VERSION ""

NS_ :

BS_:

BU_: Vector__XXX

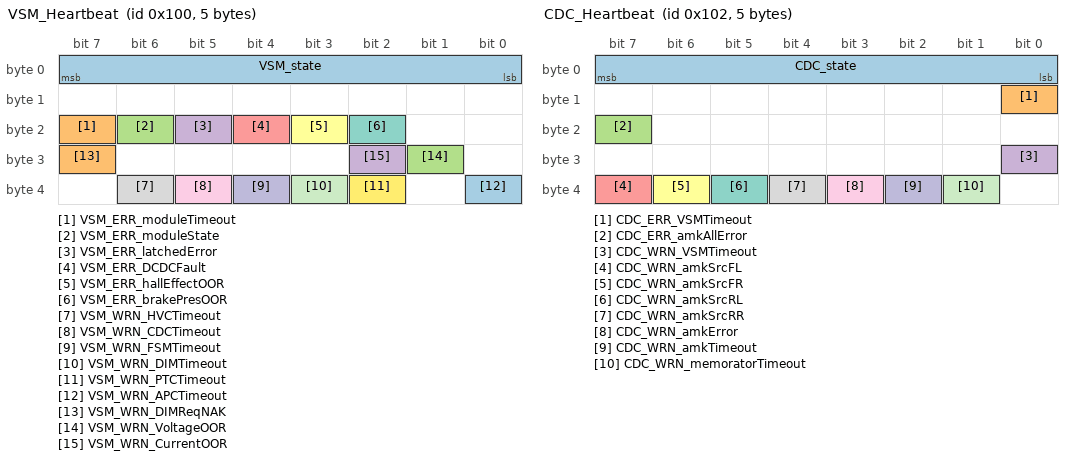
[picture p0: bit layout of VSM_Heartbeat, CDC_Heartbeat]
BO_ 256 VSM_Heartbeat: 5 Vector__XXX
SG_ VSM_state : 0|8@1+ (1,0) [0|255] "" Vector__XXX
SG_ VSM_ERR_moduleTimeout : 23|1@1+ (1,0) [0|1] "" Vector__XXX
SG_ VSM_ERR_moduleState : 22|1@1+ (1,0) [0|1] "" Vector__XXX
SG_ VSM_ERR_latchedError : 21|1@1+ (1,0) [0|1] "" Vector__XXX
SG_ VSM_ERR_DCDCFault : 20|1@1+ (1,0) [0|1] "" Vector__XXX
SG_ VSM_ERR_hallEffectOOR : 19|1@1+ (1,0) [0|1] "" Vector__XXX
SG_ VSM_ERR_brakePresOOR : 18|1@1+ (1,0) [0|1] "" Vector__XXX
SG_ VSM_WRN_HVCTimeout : 38|1@1+ (1,0) [0|1] "" Vector__XXX
SG_ VSM_WRN_CDCTimeout : 37|1@1+ (1,0) [0|1] "" Vector__XXX
SG_ VSM_WRN_FSMTimeout : 36|1@1+ (1,0) [0|1] "" Vector__XXX
SG_ VSM_WRN_DIMTimeout : 35|1@1+ (1,0) [0|1] "" Vector__XXX
SG_ VSM_WRN_PTCTimeout : 34|1@1+ (1,0) [0|1] "" Vector__XXX
SG_ VSM_WRN_APCTimeout : 32|1@1+ (1,0) [0|1] "" Vector__XXX
SG_ VSM_WRN_DIMReqNAK : 31|1@1+ (1,0) [0|1] "" Vector__XXX
SG_ VSM_WRN_VoltageOOR : 25|1@1+ (1,0) [0|1] "" Vector__XXX
SG_ VSM_WRN_CurrentOOR : 26|1@1+ (1,0) [0|1] "" Vector__XXX

BO_ 272 VSM_Status: 4 Vector__XXX
SG_ VSM_internalState : 0|8@1+ (1,0) [0|255] "" Vector__XXX
SG_ VSM_ERR_HVCTimeout : 14|1@1+ (1,0) [0|1] "" Vector__XXX
SG_ VSM_ERR_CDCTimeout : 13|1@1+ (1,0) [0|1] "" Vector__XXX
SG_ VSM_ERR_FSMTimeout : 12|1@1+ (1,0) [0|1] "" Vector__XXX
SG_ VSM_ERR_DIMTimeout : 11|1@1+ (1,0) [0|1] "" Vector__XXX
SG_ VSM_ERR_PTCTimeout : 10|1@1+ (1,0) [0|1] "" Vector__XXX
SG_ VSM_ERR_APCTimeout : 8|1@1+ (1,0) [0|1] "" Vector__XXX
SG_ VSM_ERR_HVCState : 22|1@1+ (1,0) [0|1] "" Vector__XXX
SG_ VSM_ERR_CDCState : 21|1@1+ (1,0) [0|1] "" Vector__XXX
SG_ VSM_ERR_FSMState : 20|1@1+ (1,0) [0|1] "" Vector__XXX
SG_ VSM_ERR_DIMState : 19|1@1+ (1,0) [0|1] "" Vector__XXX
SG_ VSM_ERR_PTCState : 18|1@1+ (1,0) [0|1] "" Vector__XXX
SG_ VSM_ERR_APCState : 16|1@1+ (1,0) [0|1] "" Vector__XXX
SG_ VSM_ERR_latchSoftware : 26|1@1+ (1,0) [0|1] "" Vector__XXX
SG_ VSM_ERR_latchAMS : 26|1@1+ (1,0) [0|1] "" Vector__XXX
SG_ VSM_ERR_latchIMD : 25|1@1+ (1,0) [0|1] "" Vector__XXX
SG_ VSM_ERR_latchBSPD : 24|1@1+ (1,0) [0|1] "" Vector__XXX

BO_ 512 VSM_Sensors: 8 Vector__XXX
SG_ VSM_brakePressureRear : 0|16@1+ (1,0) [0|65535] "PSI" Vector__XXX
SG_ VSM_hallEffect : 16|16@1- (0.01,0) [-327.68|327.67] "A" Vector__XXX
SG_ VSM_HE_CoulombCount : 32|32@1- (1,0) [-3.4E038|3.4E038] "C" Vector__XXX

BO_ 1296 VSM_LatchedStatus: 3 Vector__XXX
SG_ VSM_latched_ERR_HVCTimeout : 7|1@1+ (1,0) [0|1] "" Vector__XXX
SG_ VSM_latched_ERR_CDCTimeout : 6|1@1+ (1,0) [0|1] "" Vector__XXX
SG_ VSM_latched_ERR_FSMTimeout : 5|1@1+ (1,0) [0|1] "" Vector__XXX
SG_ VSM_latched_ERR_PTCTimeout : 4|1@1+ (1,0) [0|1] "" Vector__XXX
SG_ VSM_latched_ERR_DIMTimeout : 3|1@1+ (1,0) [0|1] "" Vector__XXX
SG_ VSM_latched_ERR_PTCfTimeout : 2|1@1+ (1,0) [0|1] "" Vector__XXX
SG_ VSM_latched_ERR_APCTimeout : 0|1@1+ (1,0) [0|1] "" Vector__XXX
SG_ VSM_latched_ERR_HVCState : 15|1@1+ (1,0) [0|1] "" Vector__XXX
SG_ VSM_latched_ERR_CDCState : 14|1@1+ (1,0) [0|1] "" Vector__XXX
SG_ VSM_latched_ERR_FSMState : 13|1@1+ (1,0) [0|1] "" Vector__XXX
SG_ VSM_latched_ERR_PTCState : 12|1@1+ (1,0) [0|1] "" Vector__XXX
SG_ VSM_latched_ERR_DIMState : 11|1@1+ (1,0) [0|1] "" Vector__XXX
SG_ VSM_latched_ERR_PTCfState : 10|1@1+ (1,0) [0|1] "" Vector__XXX
SG_ VSM_latched_ERR_APCState : 8|1@1+ (1,0) [0|1] "" Vector__XXX
SG_ VSM_latched_ERR_latchSoftware : 18|1@1+ (1,0) [0|1] "" Vector__XXX
SG_ VSM_latched_ERR_latchAMS : 18|1@1+ (1,0) [0|1] "" Vector__XXX
SG_ VSM_latched_ERR_latchIMD : 17|1@1+ (1,0) [0|1] "" Vector__XXX
SG_ VSM_latched_ERR_latchBSPD : 16|1@1+ (1,0) [0|1] "" Vector__XXX

BO_ 1328 VSM_PowerDiagnostic: 4 Vector__XXX
SG_ VSM_busVoltage : 0|16@1+ (1,0) [0|65535] "mV" Vector__XXX
SG_ VSM_busCurrent : 16|16@1+ (1,0) [0|65535] "mA" Vector__XXX

BO_ 257 HVC_Heartbeat: 6 Vector__XXX
SG_ HVC_Mode : 16|8@1+ (1,0) [0|255] "" Vector__XXX
SG_ HVC_State : 24|8@1+ (1,0) [0|255] "" Vector__XXX
SG_ HVC_Uptime : 40|8@1+ (1,0) [0|255] "s" Vector__XXX
SG_ HVC_ERR_PACK_UNDERVOLT : 0|1@1+ (1,0) [0|1] "" Vector__XXX
SG_ HVC_ERR_PACK_OVERVOLT : 1|1@1+ (1,0) [0|1] "" Vector__XXX
SG_ HVC_ERR_PACK_OVERCURRENT : 3|1@1+ (1,0) [0|1] "" Vector__XXX
SG_ HVC_ERR_CELL_UNDERVOLT : 4|1@1+ (1,0) [0|1] "" Vector__XXX
SG_ HVC_ERR_CELL_OVERVOLT : 5|1@1+ (1,0) [0|1] "" Vector__XXX
SG_ HVC_ERR_CELL_OVERTEMP : 6|1@1+ (1,0) [0|1] "" Vector__XXX
SG_ HVC_ERR_BMB_FAULT : 7|1@1+ (1,0) [0|1] "" Vector__XXX
SG_ HVC_ERR_BMB_TIMEOUT : 8|1@1+ (1,0) [0|1] "" Vector__XXX
SG_ HVC_ERR_CAN_TIMEOUT : 9|1@1+ (1,0) [0|1] "" Vector__XXX
SG_ HVC_ERR_RELAY : 12|1@1+ (1,0) [0|1] "" Vector__XXX
SG_ HVC_ERR_LV_UNDERVOLT : 13|1@1+ (1,0) [0|1] "" Vector__XXX
SG_ HVC_dischargeClosed : 32|1@1+ (1,0) [0|1] "" Vector__XXX
SG_ HVC_prechargeClosed : 33|1@1+ (1,0) [0|1] "" Vector__XXX
SG_ HVC_negAIRClosed : 34|1@1+ (1,0) [0|1] "" Vector__XXX
SG_ HVC_posAIRClosed : 35|1@1+ (1,0) [0|1] "" Vector__XXX
SG_ HVC_dischargeError : 36|1@1+ (1,0) [0|1] "" Vector__XXX
SG_ HVC_prechargeError : 37|1@1+ (1,0) [0|1] "" Vector__XXX
SG_ HVC_negAIRError : 38|1@1+ (1,0) [0|1] "" Vector__XXX
SG_ HVC_posAIRError : 39|1@1+ (1,0) [0|1] "" Vector__XXX

BO_ 304 HVC_Command: 1 Vector__XXX
SG_ HVC_modeRequest : 0|8@1+ (1,0) [0|255] "" Vector__XXX

BO_ 258 CDC_Heartbeat: 5 Vector__XXX
SG_ CDC_state : 0|8@1+ (1,0) [0|255] "" Vector__XXX
SG_ CDC_ERR_VSMTimeout : 8|1@1+ (1,0) [0|1] "" Vector__XXX
SG_ CDC_ERR_amkAllError : 23|1@1+ (1,0) [0|1] "" Vector__XXX
SG_ CDC_WRN_VSMTimeout : 24|1@1+ (1,0) [0|1] "" Vector__XXX
SG_ CDC_WRN_amkSrcFL : 39|1@1+ (1,0) [0|1] "" Vector__XXX
SG_ CDC_WRN_amkSrcFR : 38|1@1+ (1,0) [0|1] "" Vector__XXX
SG_ CDC_WRN_amkSrcRL : 37|1@1+ (1,0) [0|1] "" Vector__XXX
SG_ CDC_WRN_amkSrcRR : 36|1@1+ (1,0) [0|1] "" Vector__XXX
SG_ CDC_WRN_amkError : 35|1@1+ (1,0) [0|1] "" Vector__XXX
SG_ CDC_WRN_amkTimeout : 34|1@1+ (1,0) [0|1] "" Vector__XXX
SG_ CDC_WRN_memoratorTimeout : 33|1@1+ (1,0) [0|1] "" Vector__XXX

BO_ 1298 CDC_MotorTemps: 4 Vector__XXX
SG_ CDC_motorTemp : 0|16@1- (0.1,0) [-3276.8|3276.7] "C" Vector__XXX
SG_ CDC_mcMaxInternalTemp : 16|16@1- (0.1,0) [-3276.8|3276.7] "C" Vector__XXX

BO_ 1282 CDC_MCFaults: 8 Vector__XXX
SG_ POST_ERR_HWDesat : 0|1@1+ (1,0) [0|1] "" Vector__XXX
SG_ POST_ERR_HWOverCurr : 1|1@1+ (1,0) [0|1] "" Vector__XXX
SG_ POST_ERR_AccelShort : 2|1@1+ (1,0) [0|1] "" Vector__XXX
SG_ POST_ERR_AccelOpen : 3|1@1+ (1,0) [0|1] "" Vector__XXX
SG_ POST_ERR_CurrSensLo : 4|1@1+ (1,0) [0|1] "" Vector__XXX
SG_ POST_ERR_CurrSensHi : 5|1@1+ (1,0) [0|1] "" Vector__XXX
SG_ POST_ERR_Module_TempLo : 6|1@1+ (1,0) [0|1] "" Vector__XXX
SG_ POST_ERR_Module_TempHi : 7|1@1+ (1,0) [0|1] "" Vector__XXX
SG_ POST_ERR_CtrlPCB_TempLo : 8|1@1+ (1,0) [0|1] "" Vector__XXX
SG_ POST_ERR_CtrlPCB_TempHi : 9|1@1+ (1,0) [0|1] "" Vector__XXX
SG_ POST_ERR_GateDrPCB_TempLo : 10|1@1+ (1,0) [0|1] "" Vector__XXX
SG_ POST_ERR_GateDrPCB_TempHi : 11|1@1+ (1,0) [0|1] "" Vector__XXX
SG_ POST_ERR_5V_SensVoltLo : 12|1@1+ (1,0) [0|1] "" Vector__XXX
SG_ POST_ERR_5V_SensVoltHi : 13|1@1+ (1,0) [0|1] "" Vector__XXX
SG_ POST_ERR_12V_SensVoltLo : 14|1@1+ (1,0) [0|1] "" Vector__XXX
SG_ POST_ERR_12V_SensVoltHi : 15|1@1+ (1,0) [0|1] "" Vector__XXX
SG_ POST_ERR_2V5_SensVoltLo : 16|1@1+ (1,0) [0|1] "" Vector__XXX
SG_ POST_ERR_2V5_SensVoltHi : 17|1@1+ (1,0) [0|1] "" Vector__XXX
SG_ POST_ERR_1V5_SensVoltLo : 18|1@1+ (1,0) [0|1] "" Vector__XXX
SG_ POST_ERR_1V5_SensVoltHi : 19|1@1+ (1,0) [0|1] "" Vector__XXX
SG_ POST_ERR_DCBusVoltHi : 20|1@1+ (1,0) [0|1] "" Vector__XXX
SG_ POST_ERR_DCBusVoltLo : 21|1@1+ (1,0) [0|1] "" Vector__XXX
SG_ POST_ERR_PreChgTimeout : 22|1@1+ (1,0) [0|1] "" Vector__XXX
SG_ POST_ERR_PreChgVoltFail : 23|1@1+ (1,0) [0|1] "" Vector__XXX
SG_ POST_ERR_EEPROM_ChecksumInvalid : 24|1@1+ (1,0) [0|1] "" Vector__XXX
SG_ POST_ERR_EEPROM_DataOOR : 25|1@1+ (1,0) [0|1] "" Vector__XXX
SG_ POST_ERR_EEPROM_UpdateRequired : 26|1@1+ (1,0) [0|1] "" Vector__XXX
SG_ POST_ERR_BrakeShort : 30|1@1+ (1,0) [0|1] "" Vector__XXX
SG_ POST_ERR_BrakeOpen : 31|1@1+ (1,0) [0|1] "" Vector__XXX
SG_ RUN_ERROR_MotorOverspeed : 32|1@1+ (1,0) [0|1] "" Vector__XXX
SG_ RUN_ERROR_OverCurrent : 33|1@1+ (1,0) [0|1] "" Vector__XXX
SG_ RUN_ERROR_OverVoltage : 34|1@1+ (1,0) [0|1] "" Vector__XXX
SG_ RUN_ERROR_Inverter_OverTemp : 35|1@1+ (1,0) [0|1] "" Vector__XXX
SG_ RUN_ERROR_AccelInputShort : 36|1@1+ (1,0) [0|1] "" Vector__XXX
SG_ RUN_ERROR_AccelInputOpen : 37|1@1+ (1,0) [0|1] "" Vector__XXX
SG_ RUN_ERROR_DirectionCommand : 38|1@1+ (1,0) [0|1] "" Vector__XXX
SG_ RUN_ERROR_InverterTimeout : 39|1@1+ (1,0) [0|1] "" Vector__XXX
SG_ RUN_ERROR_HWDesat : 40|1@1+ (1,0) [0|1] "" Vector__XXX
SG_ RUN_ERROR_HWOverCurrent : 41|1@1+ (1,0) [0|1] "" Vector__XXX
SG_ RUN_ERROR_UnderVolt : 42|1@1+ (1,0) [0|1] "" Vector__XXX
SG_ RUN_ERROR_CANMessageLost : 43|1@1+ (1,0) [0|1] "" Vector__XXX
SG_ RUN_ERROR_Motor_OverTemp : 44|1@1+ (1,0) [0|1] "" Vector__XXX
SG_ RUN_ERROR_BrakeInputShort : 48|1@1+ (1,0) [0|1] "" Vector__XXX
SG_ RUN_ERROR_BrakeInputOpen : 49|1@1+ (1,0) [0|1] "" Vector__XXX
SG_ RUN_ERROR_ModuleA_OverTemp : 50|1@1+ (1,0) [0|1] "" Vector__XXX
SG_ RUN_ERROR_ModuleB_OverTemp : 51|1@1+ (1,0) [0|1] "" Vector__XXX
SG_ RUN_ERROR_ModuleC_OverTemp : 52|1@1+ (1,0) [0|1] "" Vector__XXX
SG_ RUN_ERROR_PCB_OverTemp : 53|1@1+ (1,0) [0|1] "" Vector__XXX
SG_ RUN_ERROR_GateDrBoard1_OverTemp : 54|1@1+ (1,0) [0|1] "" Vector__XXX
SG_ RUN_ERROR_GateDrBoard2_OverTemp : 55|1@1+ (1,0) [0|1] "" Vector__XXX
SG_ RUN_ERROR_GateDrBoard3_OverTemp : 56|1@1+ (1,0) [0|1] "" Vector__XXX
SG_ RUN_ERROR_CurrSensFault : 57|1@1+ (1,0) [0|1] "" Vector__XXX
SG_ RUN_ERROR_ResolverDisconnected : 62|1@1+ (1,0) [0|1] "" Vector__XXX
SG_ RUN_ERROR_InvtrDischargeActive : 63|1@1+ (1,0) [0|1] "" Vector__XXX

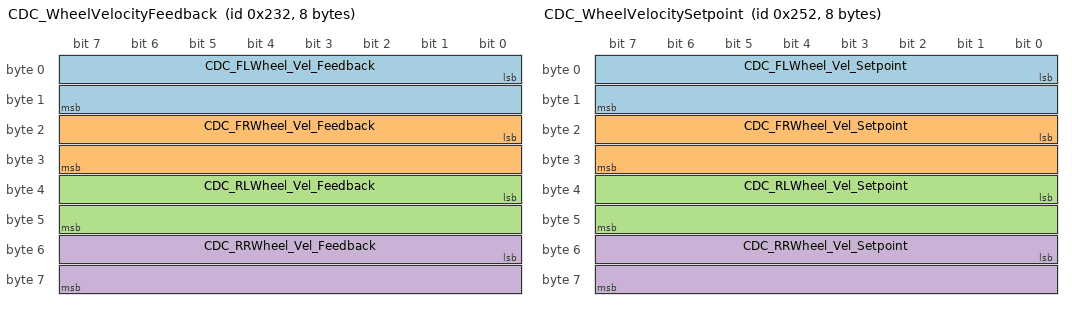
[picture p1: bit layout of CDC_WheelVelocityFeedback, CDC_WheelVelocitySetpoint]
BO_ 562 CDC_WheelVelocityFeedback: 8 Vector__XXX
SG_ CDC_FLWheel_Vel_Feedback : 0|16@1- (0.1,0) [-3276.8|3276.7] "rpm" Vector__XXX
SG_ CDC_FRWheel_Vel_Feedback : 16|16@1- (0.1,0) [-3276.8|3276.7] "rpm" Vector__XXX
SG_ CDC_RLWheel_Vel_Feedback : 32|16@1- (0.1,0) [-3276.8|3276.7] "rpm" Vector__XXX
SG_ CDC_RRWheel_Vel_Feedback : 48|16@1- (0.1,0) [-3276.8|3276.7] "rpm" Vector__XXX

BO_ 594 CDC_WheelVelocitySetpoint: 8 Vector__XXX
SG_ CDC_FLWheel_Vel_Setpoint : 0|16@1- (0.1,0) [-3276.8|3276.7] "rpm" Vector__XXX
SG_ CDC_FRWheel_Vel_Setpoint : 16|16@1- (0.1,0) [-3276.8|3276.7] "rpm" Vector__XXX
SG_ CDC_RLWheel_Vel_Setpoint : 32|16@1- (0.1,0) [-3276.8|3276.7] "rpm" Vector__XXX
SG_ CDC_RRWheel_Vel_Setpoint : 48|16@1- (0.1,0) [-3276.8|3276.7] "rpm" Vector__XXX

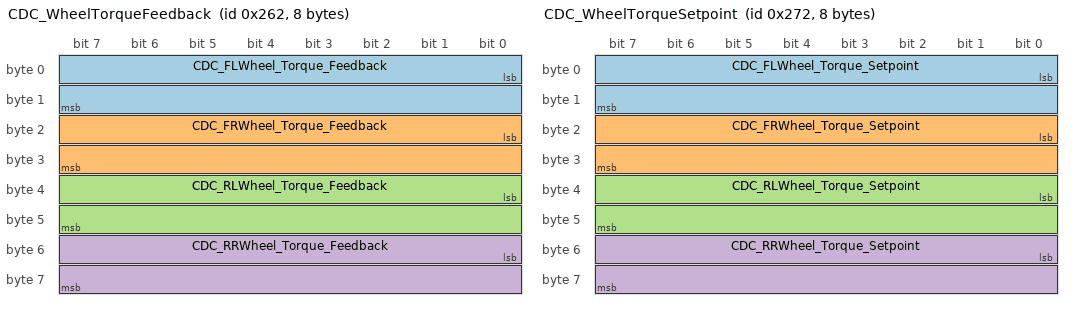
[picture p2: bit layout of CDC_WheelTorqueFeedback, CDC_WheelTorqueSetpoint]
BO_ 610 CDC_WheelTorqueFeedback: 8 Vector__XXX
SG_ CDC_FLWheel_Torque_Feedback : 0|16@1- (0.1,0) [-3276.8|3276.7] "Nm" Vector__XXX
SG_ CDC_FRWheel_Torque_Feedback : 16|16@1- (0.1,0) [-3276.8|3276.7] "Nm" Vector__XXX
SG_ CDC_RLWheel_Torque_Feedback : 32|16@1- (0.1,0) [-3276.8|3276.7] "Nm" Vector__XXX
SG_ CDC_RRWheel_Torque_Feedback : 48|16@1- (0.1,0) [-3276.8|3276.7] "Nm" Vector__XXX

BO_ 626 CDC_WheelTorqueSetpoint: 8 Vector__XXX
SG_ CDC_FLWheel_Torque_Setpoint : 0|16@1- (0.1,0) [-3276.8|3276.7] "Nm" Vector__XXX
SG_ CDC_FRWheel_Torque_Setpoint : 16|16@1- (0.1,0) [-3276.8|3276.7] "Nm" Vector__XXX
SG_ CDC_RLWheel_Torque_Setpoint : 32|16@1- (0.1,0) [-3276.8|3276.7] "Nm" Vector__XXX
SG_ CDC_RRWheel_Torque_Setpoint : 48|16@1- (0.1,0) [-3276.8|3276.7] "Nm" Vector__XXX

BO_ 642 CDC_PosePosition: 8 Vector__XXX
SG_ CDC_Latitude : 0|32@1- (1,0) [-3.4E038|3.4E038] "deg" Vector__XXX
SG_ CDC_Longitude : 32|32@1- (1,0) [-3.4E038|3.4E038] "deg" Vector__XXX

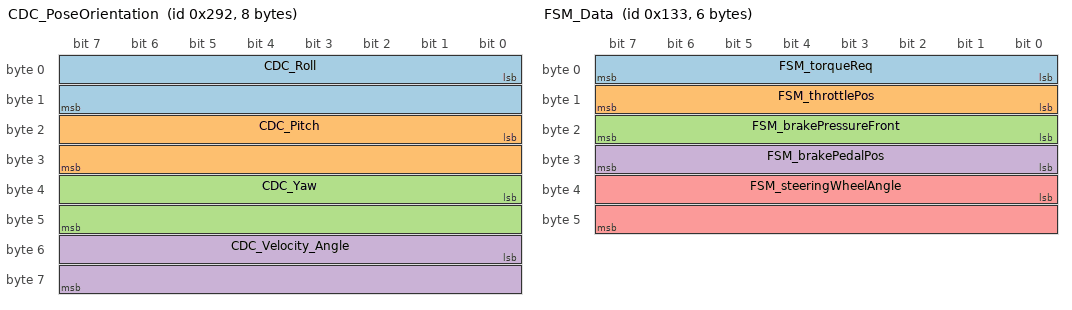
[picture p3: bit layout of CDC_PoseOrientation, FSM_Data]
BO_ 658 CDC_PoseOrientation: 8 Vector__XXX
SG_ CDC_Roll : 0|16@1- (0.1,0) [-3276.8|3276.7] "deg" Vector__XXX
SG_ CDC_Pitch : 16|16@1- (0.1,0) [-3276.8|3276.7] "deg" Vector__XXX
SG_ CDC_Yaw : 32|16@1- (0.1,0) [-3276.8|3276.7] "deg" Vector__XXX
SG_ CDC_Velocity_Angle : 48|16@1- (0.1,0) [-3276.8|3276.7] "deg" Vector__XXX

BO_ 674 CDC_PoseVelocity: 6 Vector__XXX
SG_ CDC_LongitudinalVelocity : 0|16@1- (0.01,0) [-327.68|327.67] "mps" Vector__XXX
SG_ CDC_LateralVelocity : 16|16@1- (0.01,0) [-327.68|327.67] "mps" Vector__XXX
SG_ CDC_VerticalVelocity : 32|16@1- (0.01,0) [-327.68|327.67] "mps" Vector__XXX

BO_ 690 CDC_PoseAcceleration: 6 Vector__XXX
SG_ CDC_LongitudinalAcceleration : 0|16@1- (0.01,0) [-327.68|327.67] "mps2" Vector__XXX
SG_ CDC_LateralAcceleration : 16|16@1- (0.01,0) [-327.68|327.67] "mps2" Vector__XXX
SG_ CDC_VerticalAcceleration : 32|16@1- (0.01,0) [-327.68|327.67] "mps2" Vector__XXX

BO_ 773 CDC_PowerSense: 8 Vector__XXX
SG_ CDC_PowerSenseCurrent : 0|16@1- (1,0) [-32768|32767] "dA" Vector__XXX
SG_ CDC_PowerSenseVoltage : 16|16@1- (1,0) [-32768|32767] "cV" Vector__XXX
SG_ CDC_PowerSensePower : 32|32@1- (1,0) [-2147483648|2147483647] "W" Vector__XXX

BO_ 259 FSM_Heartbeat: 5 Vector__XXX
SG_ FSM_state : 0|8@1+ (1,0) [0|255] "" Vector__XXX
SG_ FSM_ERR_VSMTimeout : 8|1@1+ (1,0) [0|1] "" Vector__XXX
SG_ FSM_WRN_VSMTimeout : 24|1@1+ (1,0) [0|1] "" Vector__XXX
SG_ FSM_WRN_VoltageOOR : 25|1@1+ (1,0) [0|1] "" Vector__XXX
SG_ FSM_WRN_CurrentOOR : 26|1@1+ (1,0) [0|1] "" Vector__XXX
SG_ FSM_WRN_BrakePositionOOR : 35|1@1+ (1,0) [0|1] "" Vector__XXX
SG_ FSM_WRN_LeftTPosOOR : 36|1@1+ (1,0) [0|1] "" Vector__XXX
SG_ FSM_WRN_RightTPosOOR : 37|1@1+ (1,0) [0|1] "" Vector__XXX
SG_ FSM_WRN_BPPFault : 38|1@1+ (1,0) [0|1] "" Vector__XXX
SG_ FSM_WRN_TPosImplausible : 39|1@1+ (1,0) [0|1] "" Vector__XXX
SG_ FSM_WRN_SSModule : 27|1@1+ (1,0) [0|1] "" Vector__XXX
SG_ FSM_WRN_SSCockpit : 28|1@1+ (1,0) [0|1] "" Vector__XXX
SG_ FSM_WRN_SSFrHub : 29|1@1+ (1,0) [0|1] "" Vector__XXX
SG_ FSM_WRN_SSInertia : 30|1@1+ (1,0) [0|1] "" Vector__XXX
SG_ FSM_WRN_SSFlHub : 31|1@1+ (1,0) [0|1] "" Vector__XXX
SG_ FSM_WRN_SSBots : 32|1@1+ (1,0) [0|1] "" Vector__XXX
SG_ FSM_WRN_BrakePressureOOR : 34|1@1+ (1,0) [0|1] "" Vector__XXX
SG_ FSM_WRN_SWAngleOOR : 33|1@1+ (1,0) [0|1] "" Vector__XXX

BO_ 307 FSM_Data: 6 Vector__XXX
SG_ FSM_torqueReq : 0|8@1+ (1,0) [0|255] "" Vector__XXX
SG_ FSM_throttlePos : 8|8@1+ (1,0) [0|255] "" Vector__XXX
SG_ FSM_brakePressureFront : 16|8@1+ (1,0) [0|255] "PSI" Vector__XXX
SG_ FSM_brakePedalPos : 24|8@1+ (1,0) [0|255] "%" Vector__XXX
SG_ FSM_steeringWheelAngle : 32|16@1- (1,0) [-32768|32767] "deg" Vector__XXX

BO_ 1331 FSM_PedalsADC: 6 Vector__XXX
SG_ FSM_throttlePosLeftADC : 0|16@1+ (1,0) [0|65535] "" Vector__XXX
SG_ FSM_throttlePosRightADC : 16|16@1+ (1,0) [0|65535] "" Vector__XXX
SG_ FSM_brakePosADC : 32|16@1+ (1,0) [0|65535] "" Vector__XXX

BO_ 1347 FSM_SensorsADC: 4 Vector__XXX
SG_ FSM_brakePressureFrontADC : 0|16@1+ (1,0) [0|65535] "" Vector__XXX
SG_ FSM_steeringWheelAngleADC : 16|16@1+ (1,0) [0|65535] "" Vector__XXX

BO_ 1363 FSM_PowerDiagnostic: 4 Vector__XXX
SG_ FSM_busVoltage : 0|16@1+ (1,0) [0|65535] "mV" Vector__XXX
SG_ FSM_busCurrent : 16|16@1+ (1,0) [0|65535] "mA" Vector__XXX

BO_ 260 DIM_Heartbeat: 5 Vector__XXX
SG_ DIM_state : 0|8@1+ (1,0) [0|255] "" Vector__XXX
SG_ DIM_ERR_VSMTimeout : 8|1@1+ (1,0) [0|1] "" Vector__XXX

BO_ 1333 DIM_PowerDiagnostic: 4 Vector__XXX
SG_ DIM_busVoltage : 0|16@1+ (1,0) [0|65535] "mV" Vector__XXX
SG_ DIM_busCurrent : 16|16@1+ (1,0) [0|65535] "mA" Vector__XXX

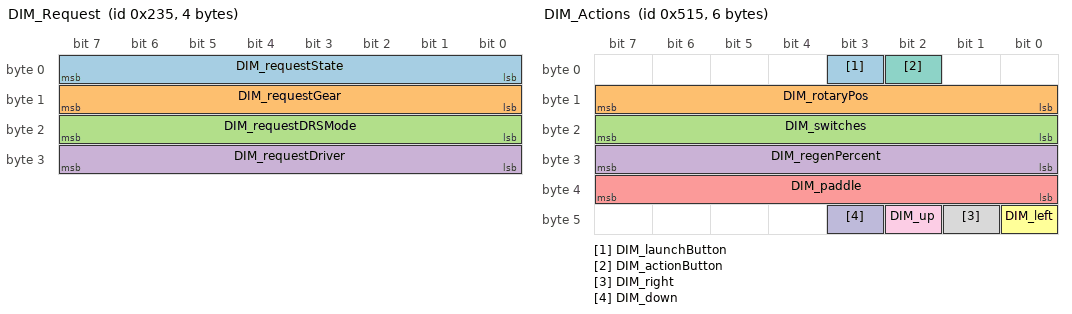
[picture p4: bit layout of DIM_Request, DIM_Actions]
BO_ 565 DIM_Request: 4 Vector__XXX
SG_ DIM_requestState : 0|8@1+ (1,0) [0|255] "" Vector__XXX
SG_ DIM_requestGear : 8|8@1+ (1,0) [0|255] "" Vector__XXX
SG_ DIM_requestDRSMode : 16|8@1+ (1,0) [0|255] "" Vector__XXX
SG_ DIM_requestDriver : 24|8@1+ (1,0) [0|255] "" Vector__XXX

BO_ 1301 DIM_Actions: 6 Vector__XXX
SG_ DIM_launchButton : 3|1@1+ (1,0) [0|1] "" Vector__XXX
SG_ DIM_rotaryPos : 8|8@1+ (1,0) [0|255] "" Vector__XXX
SG_ DIM_switches : 16|8@1+ (1,0) [0|255] "" Vector__XXX
SG_ DIM_regenPercent : 24|8@1+ (1,0) [0|255] "percent" Vector__XXX
SG_ DIM_paddle : 32|8@1+ (1,0) [0|255] "" Vector__XXX
SG_ DIM_left : 40|1@1+ (1,0) [0|1] "" Vector__XXX
SG_ DIM_actionButton : 2|1@1+ (1,0) [0|1] "" Vector__XXX
SG_ DIM_right : 41|1@1+ (1,0) [0|1] "" Vector__XXX
SG_ DIM_up : 42|1@1+ (1,0) [0|1] "" Vector__XXX
SG_ DIM_down : 43|1@1+ (1,0) [0|1] "" Vector__XXX

BO_ 1349 DIM_Acknowledge: 4 Vector__XXX
SG_ DIM_Acknowledge : 0|8@1+ (1,0) [0|255] "" Vector__XXX

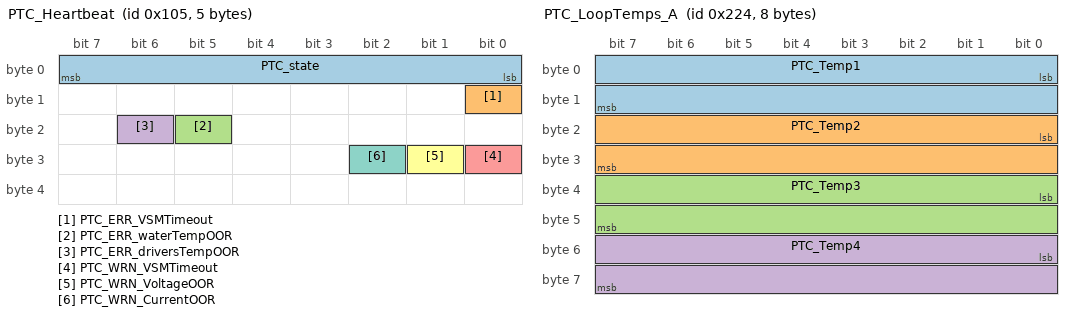
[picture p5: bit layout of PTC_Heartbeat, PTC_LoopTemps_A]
BO_ 261 PTC_Heartbeat: 5 Vector__XXX
SG_ PTC_state : 0|8@1+ (1,0) [0|255] "" Vector__XXX
SG_ PTC_ERR_VSMTimeout : 8|1@1+ (1,0) [0|1] "" Vector__XXX
SG_ PTC_ERR_waterTempOOR : 21|1@1+ (1,0) [0|1] "" Vector__XXX
SG_ PTC_ERR_driversTempOOR : 22|1@1+ (1,0) [0|1] "" Vector__XXX
SG_ PTC_WRN_VSMTimeout : 24|1@1+ (1,0) [0|1] "" Vector__XXX
SG_ PTC_WRN_VoltageOOR : 25|1@1+ (1,0) [0|1] "" Vector__XXX
SG_ PTC_WRN_CurrentOOR : 26|1@1+ (1,0) [0|1] "" Vector__XXX

BO_ 548 PTC_LoopTemps_A: 8 Vector__XXX
SG_ PTC_Temp1 : 0|16@1+ (1,0) [0|65535] "dC" Vector__XXX
SG_ PTC_Temp2 : 16|16@1+ (1,0) [0|65535] "dC" Vector__XXX
SG_ PTC_Temp3 : 32|16@1+ (1,0) [0|65535] "dC" Vector__XXX
SG_ PTC_Temp4 : 48|16@1+ (1,0) [0|65535] "dC" Vector__XXX

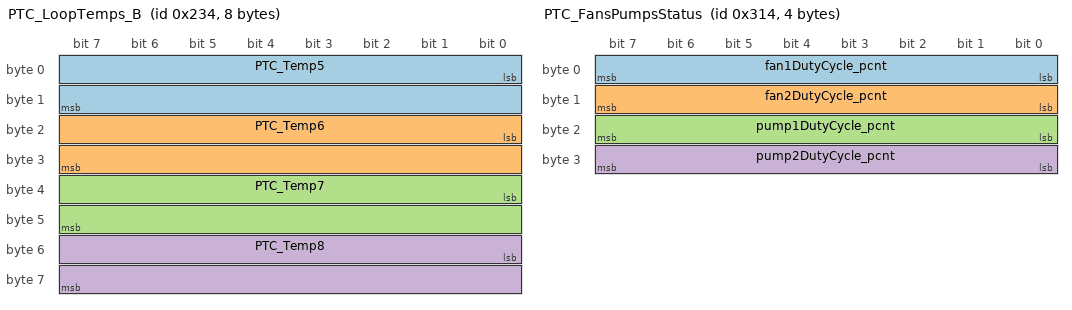
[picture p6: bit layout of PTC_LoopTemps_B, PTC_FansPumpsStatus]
BO_ 564 PTC_LoopTemps_B: 8 Vector__XXX
SG_ PTC_Temp5 : 0|16@1+ (1,0) [0|65535] "dC" Vector__XXX
SG_ PTC_Temp6 : 16|16@1+ (1,0) [0|65535] "dC" Vector__XXX
SG_ PTC_Temp7 : 32|16@1+ (1,0) [0|65535] "dC" Vector__XXX
SG_ PTC_Temp8 : 48|16@1+ (1,0) [0|65535] "dC" Vector__XXX

BO_ 580 PTC_LoopTemps_C: 2 Vector__XXX
SG_ PTC_Temp9 : 0|16@1+ (1,0) [0|65535] "dC" Vector__XXX

BO_ 788 PTC_FansPumpsStatus: 4 Vector__XXX
SG_ fan1DutyCycle_pcnt : 0|8@1+ (1,0) [0|255] "percent" Vector__XXX
SG_ fan2DutyCycle_pcnt : 8|8@1+ (1,0) [0|255] "percent" Vector__XXX
SG_ pump1DutyCycle_pcnt : 16|8@1+ (1,0) [0|255] "percent" Vector__XXX
SG_ pump2DutyCycle_pcnt : 24|8@1+ (1,0) [0|255] "percent" Vector__XXX

BO_ 1332 PTC_PowerDiagnostic: 6 Vector__XXX
SG_ PTC_logicVoltage : 0|16@1+ (1,0) [0|65535] "mV" Vector__XXX
SG_ PTC_loadVoltage : 16|16@1+ (1,0) [0|65535] "mV" Vector__XXX
SG_ PTC_loadCurrent : 32|16@1+ (1,0) [0|65535] "mA" Vector__XXX

BO_ 769 BMS_Pack_Voltages: 8 Vector__XXX
SG_ BMS_Batt_Voltage : 0|32@1- (0.001,0) [-2147483.648|2147483.647] "V" Vector__XXX
SG_ BMS_HV_Voltage : 32|32@1- (0.001,0) [-2147483.648|2147483.647] "V" Vector__XXX

BO_ 770 BMS_Pack_Currents: 8 Vector__XXX
SG_ BMS_Current_Instant : 0|32@1- (1,0) [-2147483648|2147483647] "mA" Vector__XXX
SG_ BMS_Current_Average : 32|32@1- (1,0) [-2147483648|2147483647] "mA" Vector__XXX

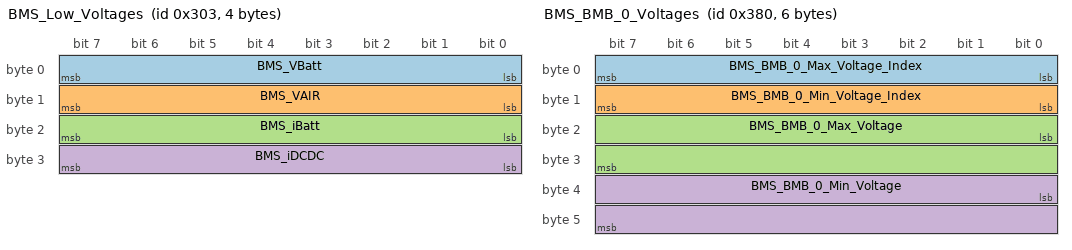
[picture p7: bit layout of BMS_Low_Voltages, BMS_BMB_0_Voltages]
BO_ 771 BMS_Low_Voltages: 4 Vector__XXX
SG_ BMS_VBatt : 0|8@1+ (0.1333333,0) [0|33.9999915] "V" Vector__XXX
SG_ BMS_VAIR : 8|8@1+ (0.1333333,0) [0|33.9999915] "V" Vector__XXX
SG_ BMS_iBatt : 16|8@1+ (0.1333333,0) [0|33.9999915] "mA" Vector__XXX
SG_ BMS_iDCDC : 24|8@1+ (0.1333333,0) [0|33.9999915] "mA" Vector__XXX

BO_ 896 BMS_BMB_0_Voltages: 6 Vector__XXX
SG_ BMS_BMB_0_Max_Voltage_Index : 0|8@1+ (1,0) [0|255] "" Vector__XXX
SG_ BMS_BMB_0_Min_Voltage_Index : 8|8@1+ (1,0) [0|255] "" Vector__XXX
SG_ BMS_BMB_0_Max_Voltage : 16|16@1+ (1,0) [0|65535] "mV" Vector__XXX
SG_ BMS_BMB_0_Min_Voltage : 32|16@1+ (1,0) [0|65535] "mV" Vector__XXX

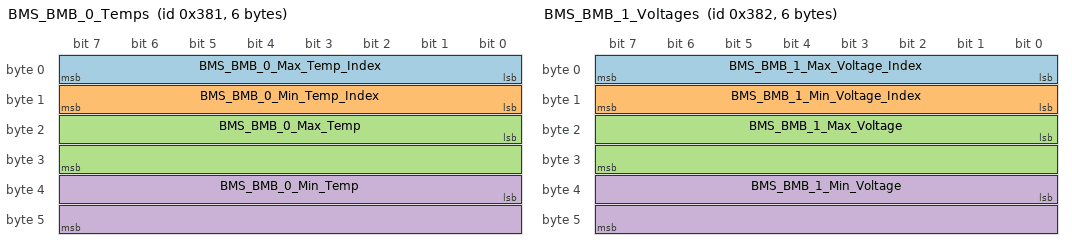
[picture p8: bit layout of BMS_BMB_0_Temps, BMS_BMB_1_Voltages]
BO_ 897 BMS_BMB_0_Temps: 6 Vector__XXX
SG_ BMS_BMB_0_Max_Temp_Index : 0|8@1+ (1,0) [0|255] "" Vector__XXX
SG_ BMS_BMB_0_Min_Temp_Index : 8|8@1+ (1,0) [0|255] "" Vector__XXX
SG_ BMS_BMB_0_Max_Temp : 16|16@1- (1,0) [-32768|32767] "" Vector__XXX
SG_ BMS_BMB_0_Min_Temp : 32|16@1- (1,0) [-32768|32767] "" Vector__XXX

BO_ 898 BMS_BMB_1_Voltages: 6 Vector__XXX
SG_ BMS_BMB_1_Max_Voltage_Index : 0|8@1+ (1,0) [0|255] "" Vector__XXX
SG_ BMS_BMB_1_Min_Voltage_Index : 8|8@1+ (1,0) [0|255] "" Vector__XXX
SG_ BMS_BMB_1_Max_Voltage : 16|16@1+ (1,0) [0|65535] "mV" Vector__XXX
SG_ BMS_BMB_1_Min_Voltage : 32|16@1+ (1,0) [0|65535] "mV" Vector__XXX

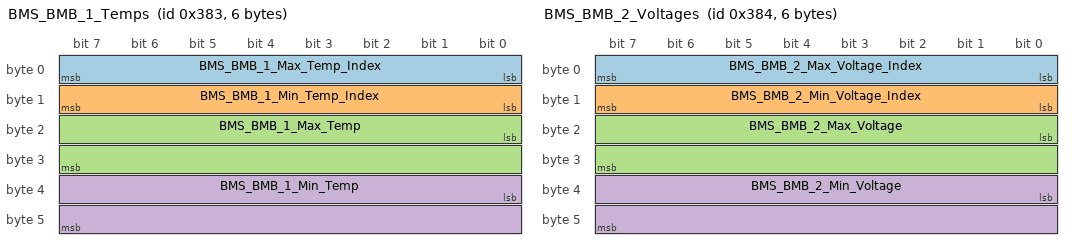
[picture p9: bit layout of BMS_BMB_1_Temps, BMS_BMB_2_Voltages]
BO_ 899 BMS_BMB_1_Temps: 6 Vector__XXX
SG_ BMS_BMB_1_Max_Temp_Index : 0|8@1+ (1,0) [0|255] "" Vector__XXX
SG_ BMS_BMB_1_Min_Temp_Index : 8|8@1+ (1,0) [0|255] "" Vector__XXX
SG_ BMS_BMB_1_Max_Temp : 16|16@1- (1,0) [-32768|32767] "" Vector__XXX
SG_ BMS_BMB_1_Min_Temp : 32|16@1- (1,0) [-32768|32767] "" Vector__XXX

BO_ 900 BMS_BMB_2_Voltages: 6 Vector__XXX
SG_ BMS_BMB_2_Max_Voltage_Index : 0|8@1+ (1,0) [0|255] "" Vector__XXX
SG_ BMS_BMB_2_Min_Voltage_Index : 8|8@1+ (1,0) [0|255] "" Vector__XXX
SG_ BMS_BMB_2_Max_Voltage : 16|16@1+ (1,0) [0|65535] "mV" Vector__XXX
SG_ BMS_BMB_2_Min_Voltage : 32|16@1+ (1,0) [0|65535] "mV" Vector__XXX

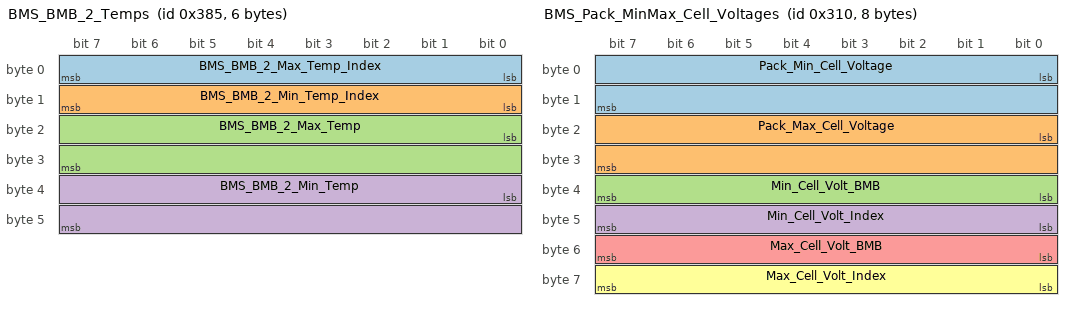
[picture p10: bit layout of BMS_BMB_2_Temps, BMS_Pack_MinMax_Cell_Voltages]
BO_ 901 BMS_BMB_2_Temps: 6 Vector__XXX
SG_ BMS_BMB_2_Max_Temp_Index : 0|8@1+ (1,0) [0|255] "" Vector__XXX
SG_ BMS_BMB_2_Min_Temp_Index : 8|8@1+ (1,0) [0|255] "" Vector__XXX
SG_ BMS_BMB_2_Max_Temp : 16|16@1- (1,0) [-32768|32767] "" Vector__XXX
SG_ BMS_BMB_2_Min_Temp : 32|16@1- (1,0) [-32768|32767] "" Vector__XXX

BO_ 902 BMS_BMB_3_Voltages: 6 Vector__XXX
SG_ BMS_BMB_3_Max_Voltage_Index : 0|8@1+ (1,0) [0|255] "" Vector__XXX
SG_ BMS_BMB_3_Min_Voltage_Index : 8|8@1+ (1,0) [0|255] "" Vector__XXX
SG_ BMS_BMB_3_Max_Voltage : 16|16@1+ (1,0) [0|65535] "mV" Vector__XXX
SG_ BMS_BMB_3_Min_Voltage : 32|16@1+ (1,0) [0|65535] "mV" Vector__XXX

BO_ 903 BMS_BMB_3_Temps: 6 Vector__XXX
SG_ BMS_BMB_3_Max_Temp_Index : 0|8@1+ (1,0) [0|255] "" Vector__XXX
SG_ BMS_BMB_3_Min_Temp_Index : 8|8@1+ (1,0) [0|255] "" Vector__XXX
SG_ BMS_BMB_3_Max_Temp : 16|16@1- (1,0) [-32768|32767] "" Vector__XXX
SG_ BMS_BMB_3_Min_Temp : 32|16@1- (1,0) [-32768|32767] "" Vector__XXX

BO_ 904 BMS_BMB_4_Voltages: 6 Vector__XXX
SG_ BMS_BMB_4_Max_Voltage_Index : 0|8@1+ (1,0) [0|255] "" Vector__XXX
SG_ BMS_BMB_4_Min_Voltage_Index : 8|8@1+ (1,0) [0|255] "" Vector__XXX
SG_ BMS_BMB_4_Max_Voltage : 16|16@1+ (1,0) [0|65535] "mV" Vector__XXX
SG_ BMS_BMB_4_Min_Voltage : 32|16@1+ (1,0) [0|65535] "mV" Vector__XXX

BO_ 905 BMS_BMB_4_Temps: 6 Vector__XXX
SG_ BMS_BMB_4_Max_Temp_Index : 0|8@1+ (1,0) [0|255] "" Vector__XXX
SG_ BMS_BMB_4_Min_Temp_Index : 8|8@1+ (1,0) [0|255] "" Vector__XXX
SG_ BMS_BMB_4_Max_Temp : 16|16@1- (1,0) [-32768|32767] "" Vector__XXX
SG_ BMS_BMB_4_Min_Temp : 32|16@1- (1,0) [-32768|32767] "" Vector__XXX

BO_ 906 BMS_BMB_5_Voltages: 6 Vector__XXX
SG_ BMS_BMB_5_Max_Voltage_Index : 0|8@1+ (1,0) [0|255] "" Vector__XXX
SG_ BMS_BMB_5_Min_Voltage_Index : 8|8@1+ (1,0) [0|255] "" Vector__XXX
SG_ BMS_BMB_5_Max_Voltage : 16|16@1+ (1,0) [0|65535] "mV" Vector__XXX
SG_ BMS_BMB_5_Min_Voltage : 32|16@1+ (1,0) [0|65535] "mV" Vector__XXX

BO_ 907 BMS_BMB_5_Temps: 6 Vector__XXX
SG_ BMS_BMB_5_Max_Temp_Index : 0|8@1+ (1,0) [0|255] "" Vector__XXX
SG_ BMS_BMB_5_Min_Temp_Index : 8|8@1+ (1,0) [0|255] "" Vector__XXX
SG_ BMS_BMB_5_Max_Temp : 16|16@1- (1,0) [-32768|32767] "" Vector__XXX
SG_ BMS_BMB_5_Min_Temp : 32|16@1- (1,0) [-32768|32767] "" Vector__XXX

BO_ 908 BMS_BMB_6_Voltages: 6 Vector__XXX
SG_ BMS_BMB_6_Max_Voltage_Index : 0|8@1+ (1,0) [0|255] "" Vector__XXX
SG_ BMS_BMB_6_Min_Voltage_Index : 8|8@1+ (1,0) [0|255] "" Vector__XXX
SG_ BMS_BMB_6_Max_Voltage : 16|16@1+ (1,0) [0|65535] "mV" Vector__XXX
SG_ BMS_BMB_6_Min_Voltage : 32|16@1+ (1,0) [0|65535] "mV" Vector__XXX

BO_ 909 BMS_BMB_6_Temps: 6 Vector__XXX
SG_ BMS_BMB_6_Max_Temp_Index : 0|8@1+ (1,0) [0|255] "" Vector__XXX
SG_ BMS_BMB_6_Min_Temp_Index : 8|8@1+ (1,0) [0|255] "" Vector__XXX
SG_ BMS_BMB_6_Max_Temp : 16|16@1- (1,0) [-32768|32767] "" Vector__XXX
SG_ BMS_BMB_6_Min_Temp : 32|16@1- (1,0) [-32768|32767] "" Vector__XXX

BO_ 910 BMS_BMB_7_Voltages: 6 Vector__XXX
SG_ BMS_BMB_7_Max_Voltage_Index : 0|8@1+ (1,0) [0|255] "" Vector__XXX
SG_ BMS_BMB_7_Min_Voltage_Index : 8|8@1+ (1,0) [0|255] "" Vector__XXX
SG_ BMS_BMB_7_Max_Voltage : 16|16@1+ (1,0) [0|65535] "mV" Vector__XXX
SG_ BMS_BMB_7_Min_Voltage : 32|16@1+ (1,0) [0|65535] "mV" Vector__XXX

BO_ 911 BMS_BMB_7_Temps: 6 Vector__XXX
SG_ BMS_BMB_7_Max_Temp_Index : 0|8@1+ (1,0) [0|255] "" Vector__XXX
SG_ BMS_BMB_7_Min_Temp_Index : 8|8@1+ (1,0) [0|255] "" Vector__XXX
SG_ BMS_BMB_7_Max_Temp : 16|16@1- (1,0) [-32768|32767] "" Vector__XXX
SG_ BMS_BMB_7_Min_Temp : 32|16@1- (1,0) [-32768|32767] "" Vector__XXX

BO_ 912 BMS_BMB_8_Voltages: 6 Vector__XXX
SG_ BMS_BMB_8_Max_Voltage_Index : 0|8@1+ (1,0) [0|255] "" Vector__XXX
SG_ BMS_BMB_8_Min_Voltage_Index : 8|8@1+ (1,0) [0|255] "" Vector__XXX
SG_ BMS_BMB_8_Max_Voltage : 16|16@1+ (1,0) [0|65535] "mV" Vector__XXX
SG_ BMS_BMB_8_Min_Voltage : 32|16@1+ (1,0) [0|65535] "mV" Vector__XXX

BO_ 913 BMS_BMB_8_Temps: 6 Vector__XXX
SG_ BMS_BMB_8_Max_Temp_Index : 0|8@1+ (1,0) [0|255] "" Vector__XXX
SG_ BMS_BMB_8_Min_Temp_Index : 8|8@1+ (1,0) [0|255] "" Vector__XXX
SG_ BMS_BMB_8_Max_Temp : 16|16@1- (1,0) [-32768|32767] "" Vector__XXX
SG_ BMS_BMB_8_Min_Temp : 32|16@1- (1,0) [-32768|32767] "" Vector__XXX

BO_ 914 BMS_BMB_9_Voltages: 6 Vector__XXX
SG_ BMS_BMB_9_Max_Voltage_Index : 0|8@1+ (1,0) [0|255] "" Vector__XXX
SG_ BMS_BMB_9_Min_Voltage_Index : 8|8@1+ (1,0) [0|255] "" Vector__XXX
SG_ BMS_BMB_9_Max_Voltage : 16|16@1+ (1,0) [0|65535] "mV" Vector__XXX
SG_ BMS_BMB_9_Min_Voltage : 32|16@1+ (1,0) [0|65535] "mV" Vector__XXX

BO_ 915 BMS_BMB_9_Temps: 6 Vector__XXX
SG_ BMS_BMB_9_Max_Temp_Index : 0|8@1+ (1,0) [0|255] "" Vector__XXX
SG_ BMS_BMB_9_Min_Temp_Index : 8|8@1+ (1,0) [0|255] "" Vector__XXX
SG_ BMS_BMB_9_Max_Temp : 16|16@1- (1,0) [-32768|32767] "" Vector__XXX
SG_ BMS_BMB_9_Min_Temp : 32|16@1- (1,0) [-32768|32767] "" Vector__XXX

BO_ 916 BMS_BMB_10_Voltages: 6 Vector__XXX
SG_ BMS_BMB_10_Max_Voltage_Index : 0|8@1+ (1,0) [0|255] "" Vector__XXX
SG_ BMS_BMB_10_Min_Voltage_Index : 8|8@1+ (1,0) [0|255] "" Vector__XXX
SG_ BMS_BMB_10_Max_Voltage : 16|16@1+ (1,0) [0|65535] "mV" Vector__XXX
SG_ BMS_BMB_10_Min_Voltage : 32|16@1+ (1,0) [0|65535] "mV" Vector__XXX

BO_ 917 BMS_BMB_10_Temps: 6 Vector__XXX
SG_ BMS_BMB_10_Max_Temp_Index : 0|8@1+ (1,0) [0|255] "" Vector__XXX
SG_ BMS_BMB_10_Min_Temp_Index : 8|8@1+ (1,0) [0|255] "" Vector__XXX
SG_ BMS_BMB_10_Max_Temp : 16|16@1- (1,0) [-32768|32767] "" Vector__XXX
SG_ BMS_BMB_10_Min_Temp : 32|16@1- (1,0) [-32768|32767] "" Vector__XXX

BO_ 918 BMS_BMB_11_Voltages: 6 Vector__XXX
SG_ BMS_BMB_11_Max_Voltage_Index : 0|8@1+ (1,0) [0|255] "" Vector__XXX
SG_ BMS_BMB_11_Min_Voltage_Index : 8|8@1+ (1,0) [0|255] "" Vector__XXX
SG_ BMS_BMB_11_Max_Voltage : 16|16@1+ (1,0) [0|65535] "mV" Vector__XXX
SG_ BMS_BMB_11_Min_Voltage : 32|16@1+ (1,0) [0|65535] "mV" Vector__XXX

BO_ 919 BMS_BMB_11_Temps: 6 Vector__XXX
SG_ BMS_BMB_11_Max_Temp_Index : 0|8@1+ (1,0) [0|255] "" Vector__XXX
SG_ BMS_BMB_11_Min_Temp_Index : 8|8@1+ (1,0) [0|255] "" Vector__XXX
SG_ BMS_BMB_11_Max_Temp : 16|16@1- (1,0) [-32768|32767] "" Vector__XXX
SG_ BMS_BMB_11_Min_Temp : 32|16@1- (1,0) [-32768|32767] "" Vector__XXX

BO_ 920 BMS_BMB_12_Voltages: 6 Vector__XXX
SG_ BMS_BMB_12_Max_Voltage_Index : 0|8@1+ (1,0) [0|255] "" Vector__XXX
SG_ BMS_BMB_12_Min_Voltage_Index : 8|8@1+ (1,0) [0|255] "" Vector__XXX
SG_ BMS_BMB_12_Max_Voltage : 16|16@1+ (1,0) [0|65535] "mV" Vector__XXX
SG_ BMS_BMB_12_Min_Voltage : 32|16@1+ (1,0) [0|65535] "mV" Vector__XXX

BO_ 921 BMS_BMB_12_Temps: 6 Vector__XXX
SG_ BMS_BMB_12_Max_Temp_Index : 0|8@1+ (1,0) [0|255] "" Vector__XXX
SG_ BMS_BMB_12_Min_Temp_Index : 8|8@1+ (1,0) [0|255] "" Vector__XXX
SG_ BMS_BMB_12_Max_Temp : 16|16@1- (1,0) [-32768|32767] "" Vector__XXX
SG_ BMS_BMB_12_Min_Temp : 32|16@1- (1,0) [-32768|32767] "" Vector__XXX

BO_ 922 BMS_BMB_13_Voltages: 6 Vector__XXX
SG_ BMS_BMB_13_Max_Voltage_Index : 0|8@1+ (1,0) [0|255] "" Vector__XXX
SG_ BMS_BMB_13_Min_Voltage_Index : 8|8@1+ (1,0) [0|255] "" Vector__XXX
SG_ BMS_BMB_13_Max_Voltage : 16|16@1+ (1,0) [0|65535] "mV" Vector__XXX
SG_ BMS_BMB_13_Min_Voltage : 32|16@1+ (1,0) [0|65535] "mV" Vector__XXX

BO_ 923 BMS_BMB_13_Temps: 6 Vector__XXX
SG_ BMS_BMB_13_Max_Temp_Index : 0|8@1+ (1,0) [0|255] "" Vector__XXX
SG_ BMS_BMB_13_Min_Temp_Index : 8|8@1+ (1,0) [0|255] "" Vector__XXX
SG_ BMS_BMB_13_Max_Temp : 16|16@1- (1,0) [-32768|32767] "" Vector__XXX
SG_ BMS_BMB_13_Min_Temp : 32|16@1- (1,0) [-32768|32767] "" Vector__XXX

BO_ 924 BMS_BMB_14_Voltages: 6 Vector__XXX
SG_ BMS_BMB_14_Max_Voltage_Index : 0|8@1+ (1,0) [0|255] "" Vector__XXX
SG_ BMS_BMB_14_Min_Voltage_Index : 8|8@1+ (1,0) [0|255] "" Vector__XXX
SG_ BMS_BMB_14_Max_Voltage : 16|16@1+ (1,0) [0|65535] "mV" Vector__XXX
SG_ BMS_BMB_14_Min_Voltage : 32|16@1+ (1,0) [0|65535] "mV" Vector__XXX

BO_ 925 BMS_BMB_14_Temps: 6 Vector__XXX
SG_ BMS_BMB_14_Max_Temp_Index : 0|8@1+ (1,0) [0|255] "" Vector__XXX
SG_ BMS_BMB_14_Min_Temp_Index : 8|8@1+ (1,0) [0|255] "" Vector__XXX
SG_ BMS_BMB_14_Max_Temp : 16|16@1- (1,0) [-32768|32767] "" Vector__XXX
SG_ BMS_BMB_14_Min_Temp : 32|16@1- (1,0) [-32768|32767] "" Vector__XXX

BO_ 926 BMS_BMB_15_Voltages: 6 Vector__XXX
SG_ BMS_BMB_15_Max_Voltage_Index : 0|8@1+ (1,0) [0|255] "" Vector__XXX
SG_ BMS_BMB_15_Min_Voltage_Index : 8|8@1+ (1,0) [0|255] "" Vector__XXX
SG_ BMS_BMB_15_Max_Voltage : 16|16@1+ (1,0) [0|65535] "mV" Vector__XXX
SG_ BMS_BMB_15_Min_Voltage : 32|16@1+ (1,0) [0|65535] "mV" Vector__XXX

BO_ 927 BMS_BMB_15_Temps: 6 Vector__XXX
SG_ BMS_BMB_15_Max_Temp_Index : 0|8@1+ (1,0) [0|255] "" Vector__XXX
SG_ BMS_BMB_15_Min_Temp_Index : 8|8@1+ (1,0) [0|255] "" Vector__XXX
SG_ BMS_BMB_15_Max_Temp : 16|16@1- (1,0) [-32768|32767] "" Vector__XXX
SG_ BMS_BMB_15_Min_Temp : 32|16@1- (1,0) [-32768|32767] "" Vector__XXX

BO_ 784 BMS_Pack_MinMax_Cell_Voltages: 8 Vector__XXX
SG_ Pack_Min_Cell_Voltage : 0|16@1+ (1,0) [0|65535] "" Vector__XXX
SG_ Pack_Max_Cell_Voltage : 16|16@1+ (1,0) [0|65535] "" Vector__XXX
SG_ Min_Cell_Volt_BMB : 32|8@1+ (1,0) [0|255] "" Vector__XXX
SG_ Min_Cell_Volt_Index : 40|8@1+ (1,0) [0|255] "" Vector__XXX
SG_ Max_Cell_Volt_BMB : 48|8@1+ (1,0) [0|255] "" Vector__XXX
SG_ Max_Cell_Volt_Index : 56|8@1+ (1,0) [0|255] "" Vector__XXX

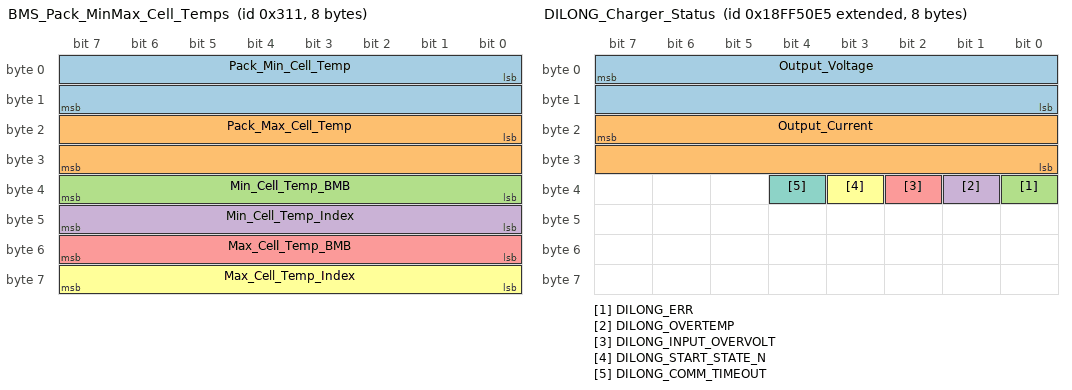
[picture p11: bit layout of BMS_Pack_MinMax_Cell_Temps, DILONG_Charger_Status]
BO_ 785 BMS_Pack_MinMax_Cell_Temps: 8 Vector__XXX
SG_ Pack_Min_Cell_Temp : 0|16@1+ (1,0) [0|65535] "" Vector__XXX
SG_ Pack_Max_Cell_Temp : 16|16@1+ (1,0) [0|65535] "" Vector__XXX
SG_ Min_Cell_Temp_BMB : 32|8@1+ (1,0) [0|255] "" Vector__XXX
SG_ Min_Cell_Temp_Index : 40|8@1+ (1,0) [0|255] "" Vector__XXX
SG_ Max_Cell_Temp_BMB : 48|8@1+ (1,0) [0|255] "" Vector__XXX
SG_ Max_Cell_Temp_Index : 56|8@1+ (1,0) [0|255] "" Vector__XXX

BO_ 2566869221 DILONG_Charger_Status: 8 Vector__XXX
SG_ Output_Voltage : 7|16@0+ (0.1,0) [0|6553.5] "V" Vector__XXX
SG_ Output_Current : 23|16@0+ (0.1,0) [0|6553.5] "A" Vector__XXX
SG_ DILONG_ERR : 32|1@1+ (1,0) [0|1] "" Vector__XXX
SG_ DILONG_OVERTEMP : 33|1@1+ (1,0) [0|1] "" Vector__XXX
SG_ DILONG_INPUT_OVERVOLT : 34|1@1+ (1,0) [0|1] "" Vector__XXX
SG_ DILONG_START_STATE_N : 35|1@1+ (1,0) [0|1] "" Vector__XXX
SG_ DILONG_COMM_TIMEOUT : 36|1@1+ (1,0) [0|1] "" Vector__XXX

BO_ 2550588916 DILONG_Charger_Control: 8 Vector__XXX
SG_ Max_Voltage : 7|16@0+ (0.1,0) [0|6553.5] "V" Vector__XXX
SG_ Max_Current : 23|16@0+ (0.1,0) [0|6553.5] "A" Vector__XXX
SG_ DILONG_Enable_N : 32|8@1+ (1,0) [0|255] "" Vector__XXX
SG_ DILONG_Battery_Mode_N : 40|8@1+ (1,0) [0|255] "" Vector__XXX

BO_ 1792 ELLIPSE_IMU_General_Status_1: 8 Vector__XXX
SG_ SBG_Time_Stamp_GS1 : 0|32@1+ (1E-006,0) [0|4294.967295] "s" Vector__XXX
SG_ SBG_General_Status : 32|16@1+ (1,0) [0|65535] "" Vector__XXX
SG_ SBG_Clock_Status : 48|16@1+ (1,0) [0|65535] "" Vector__XXX

BO_ 1793 ELLIPSE_IMU_General_Status_2: 8 Vector__XXX
SG_ SBG_Com_Status : 0|32@1+ (1,0) [0|4294967295] "" Vector__XXX
SG_ SBG_Aiding_Status : 32|32@1+ (1,0) [0|4294967295] "" Vector__XXX

BO_ 1794 ELLIPSE_IMU_General_Status_3: 6 Vector__XXX
SG_ SBG_Solution_Mode : 0|4@1+ (1,0) [0|15] "" Vector__XXX
SG_ SBG_Sol_Attitude_Valid : 4|1@1+ (1,0) [0|1] "" Vector__XXX
SG_ SBG_Sol_Heading_Valid : 5|1@1+ (1,0) [0|1] "" Vector__XXX
SG_ SBG_Sol_Velocity_Valid : 6|1@1+ (1,0) [0|1] "" Vector__XXX
SG_ SBG_Sol_Position_Valid : 7|1@1+ (1,0) [0|1] "" Vector__XXX
SG_ SBG_Sol_Vert_Ref_Used : 8|1@1+ (1,0) [0|1] "" Vector__XXX
SG_ SBG_Sol_Mag_Ref_Used : 9|1@1+ (1,0) [0|1] "" Vector__XXX
SG_ SBG_Sol_GPS1_Vel_Used : 10|1@1+ (1,0) [0|1] "" Vector__XXX
SG_ SBG_Sol_GPS1_Pos_Used : 11|1@1+ (1,0) [0|1] "" Vector__XXX
SG_ SBG_Sol_GPS1_Hdt_Used : 13|1@1+ (1,0) [0|1] "" Vector__XXX
SG_ SBG_Sol_GPS2_Vel_Used : 14|1@1+ (1,0) [0|1] "" Vector__XXX
SG_ SBG_Sol_GPS2_Pos_Used : 15|1@1+ (1,0) [0|1] "" Vector__XXX
SG_ SBG_Sol_GPS2_Hdt_Used : 17|1@1+ (1,0) [0|1] "" Vector__XXX
SG_ SBG_Sol_Odo_Used : 18|1@1+ (1,0) [0|1] "" Vector__XXX
SG_ SBG_Sol_Dvl_Bt_Used : 19|1@1+ (1,0) [0|1] "" Vector__XXX
SG_ SBG_Sol_Dvl_Wt_Used : 20|1@1+ (1,0) [0|1] "" Vector__XXX
SG_ SBG_Sol_Usbl_Used : 24|1@1+ (1,0) [0|1] "" Vector__XXX
SG_ SBG_Sol_Pressure_Used : 25|1@1+ (1,0) [0|1] "" Vector__XXX
SG_ SBG_Sol_Zupt_Used : 26|1@1+ (1,0) [0|1] "" Vector__XXX
SG_ SBG_Sol_Align_Valid : 27|1@1+ (1,0) [0|1] "" Vector__XXX
SG_ SBG_Heave_Status_GENERAL3 : 32|16@1+ (1,0) [0|65535] "" Vector__XXX

BO_ 1795 ELLIPSE_IMU_UTC_0: 8 Vector__XXX
SG_ SBG_Time_Stamp_UTC0 : 0|32@1+ (1E-006,0) [0|4294.967295] "s" Vector__XXX
SG_ SBG_Gps_Tow_UTC0 : 32|32@1+ (0.001,0) [0|4294967.295] "s" Vector__XXX

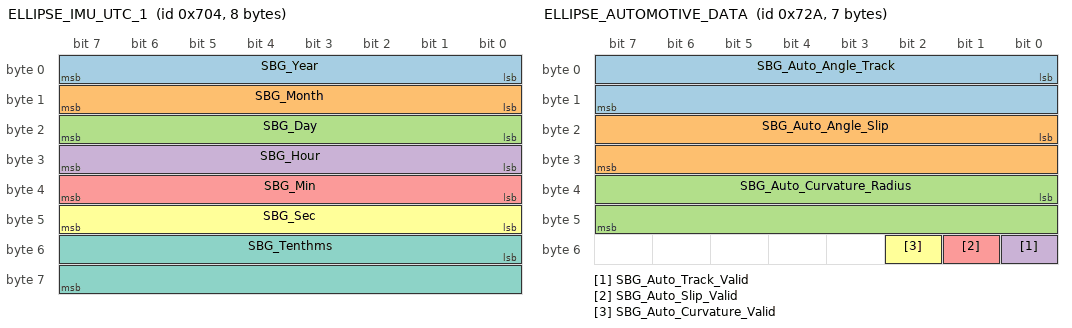
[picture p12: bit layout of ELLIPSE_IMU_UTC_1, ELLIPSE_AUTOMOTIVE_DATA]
BO_ 1796 ELLIPSE_IMU_UTC_1: 8 Vector__XXX
SG_ SBG_Year : 0|8@1+ (1,0) [0|255] "year" Vector__XXX
SG_ SBG_Month : 8|8@1+ (1,0) [0|255] "month" Vector__XXX
SG_ SBG_Day : 16|8@1+ (1,0) [0|255] "d" Vector__XXX
SG_ SBG_Hour : 24|8@1+ (1,0) [0|255] "h" Vector__XXX
SG_ SBG_Min : 32|8@1+ (1,0) [0|255] "min" Vector__XXX
SG_ SBG_Sec : 40|8@1+ (1,0) [0|255] "s" Vector__XXX
SG_ SBG_Tenthms : 48|16@1+ (0.0001,0) [0|6.5535] "s" Vector__XXX

BO_ 1808 ELLIPSE_IMU_INFO: 8 Vector__XXX
SG_ SBG_Time_Stamp_IMU : 0|32@1+ (1E-006,0) [0|4294.967295] "s" Vector__XXX
SG_ SBG_Imu_Status : 32|16@1+ (1,0) [0|65535] "" Vector__XXX
SG_ SBG_Temperature : 48|16@1- (0.01,0) [-327.68|327.67] "'C" Vector__XXX

BO_ 1809 ELLIPSE_IMU_ACCEL: 6 Vector__XXX
SG_ SBG_Accel_X : 0|16@1- (0.01,0) [-327.68|327.67] "m.s-2" Vector__XXX
SG_ SBG_Accel_Y : 16|16@1- (0.01,0) [-327.68|327.67] "m.s-2" Vector__XXX
SG_ SBG_Accel_Z : 32|16@1- (0.01,0) [-327.68|327.67] "m.s-2" Vector__XXX

BO_ 1810 ELLIPSE_IMU_GYRO: 6 Vector__XXX
SG_ SBG_Gyro_X : 0|16@1- (0.001,0) [-32.768|32.767] "rad.s-1" Vector__XXX
SG_ SBG_Gyro_Y : 16|16@1- (0.001,0) [-32.768|32.767] "rad.s-1" Vector__XXX
SG_ SBG_Gyro_Z : 32|16@1- (0.001,0) [-32.768|32.767] "rad.s-1" Vector__XXX

BO_ 1811 ELLIPSE_IMU_DELTA_VEL: 6 Vector__XXX
SG_ SBG_Delta_Vel_X : 0|16@1- (0.01,0) [-327.68|327.67] "m.s-2" Vector__XXX
SG_ SBG_Delta_Vel_Y : 16|16@1- (0.01,0) [-327.68|327.67] "m.s-2" Vector__XXX
SG_ SBG_Delta_Vel_Z : 32|16@1- (0.01,0) [-327.68|327.67] "m.s-2" Vector__XXX

BO_ 1812 ELLIPSE_IMU_DELTA_ANGLE: 6 Vector__XXX
SG_ SBG_Delta_Angle_X : 0|16@1- (0.001,0) [-32.768|32.767] "rad.s-1" Vector__XXX
SG_ SBG_Delta_Angle_Y : 16|16@1- (0.001,0) [-32.768|32.767] "rad.s-1" Vector__XXX
SG_ SBG_Delta_Angle_Z : 32|16@1- (0.001,0) [-32.768|32.767] "rad.s-1" Vector__XXX

BO_ 1824 ELLIPSE_IMU_EKF_INFO: 4 Vector__XXX
SG_ SBG_Time_Stamp_EKF : 0|32@1+ (1E-006,0) [0|4294.967295] "s" Vector__XXX

BO_ 1825 ELLIPSE_IMU_EKF_QUAT: 8 Vector__XXX
SG_ SBG_Q0 : 0|16@1- (1,0) [-32768|32767] "" Vector__XXX
SG_ SBG_Q1 : 16|16@1- (1,0) [-32768|32767] "" Vector__XXX
SG_ SBG_Q2 : 32|16@1- (1,0) [-32768|32767] "" Vector__XXX
SG_ SBG_Q3 : 48|16@1- (1,0) [-32768|32767] "" Vector__XXX

BO_ 1826 ELLIPSE_IMU_EKF_EULER: 6 Vector__XXX
SG_ SBG_Roll : 0|16@1- (0.0057295779,0) [-187.7468086272|187.7410790493] "'" Vector__XXX
SG_ SBG_Pitch : 16|16@1- (0.0057295779,0) [-187.7468086272|187.7410790493] "'" Vector__XXX
SG_ SBG_Yaw : 32|16@1- (0.0057295779,0) [-187.7468086272|187.7410790493] "'" Vector__XXX

BO_ 1827 ELLIPSE_IMU_EKF_ORIENT_ACC: 6 Vector__XXX
SG_ SBG_Roll_Acc : 0|16@1+ (0.0057295779,0) [0|375.4878876765] "'" Vector__XXX
SG_ SBG_Pitch_Acc : 16|16@1+ (0.0057295779,0) [0|375.4878876765] "'" Vector__XXX
SG_ SBG_Yaw_Acc : 32|16@1+ (0.0057295779,0) [0|375.4878876765] "'" Vector__XXX

BO_ 1828 ELLIPSE_IMU_EKF_POS: 8 Vector__XXX
SG_ SBG_Latitude : 0|32@1- (1E-007,0) [-214.7483648|214.7483647] "'" Vector__XXX
SG_ SBG_Longitude : 32|32@1- (1E-007,0) [-214.7483648|214.7483647] "'" Vector__XXX

BO_ 1829 ELLIPSE_IMU_EKF_ALTITUDE: 6 Vector__XXX
SG_ SBG_Altitude : 0|32@1- (0.001,0) [-2147483.648|2147483.647] "m" Vector__XXX
SG_ SBG_Undulation : 32|16@1- (0.005,0) [-163.84|163.835] "m" Vector__XXX

BO_ 1830 ELLIPSE_IMU_EKF_POS_ACC: 6 Vector__XXX
SG_ SBG_Latitude_Acc : 0|16@1+ (0.01,0) [0|655.35] "m" Vector__XXX
SG_ SBG_Longitude_Acc : 16|16@1+ (0.01,0) [0|655.35] "m" Vector__XXX
SG_ SBG_Altitude_Acc : 32|16@1+ (0.01,0) [0|655.35] "m" Vector__XXX

BO_ 1831 ELLIPSE_IMU_EKF_VEL: 6 Vector__XXX
SG_ SBG_Velocity_N : 0|16@1- (0.01,0) [-327.68|327.67] "m.s-1" Vector__XXX
SG_ SBG_Velocity_E : 16|16@1- (0.01,0) [-327.68|327.67] "m.s-1" Vector__XXX
SG_ SBG_Velocity_D : 32|16@1- (0.01,0) [-327.68|327.67] "m.s-1" Vector__XXX

BO_ 1833 ELLIPSE_IMU_BODY_VEL: 6 Vector__XXX
SG_ SBG_Velocity_Forward : 0|16@1- (0.01,0) [-327.68|327.67] "m.s-1" Vector__XXX
SG_ SBG_Velocity_Right : 16|16@1- (0.01,0) [-327.68|327.67] "m.s-1" Vector__XXX
SG_ SBG_Velocity_Down : 32|16@1- (0.01,0) [-327.68|327.67] "m.s-1" Vector__XXX

BO_ 1832 ELLIPSE_IMU_EKF_VEL_ACC: 6 Vector__XXX
SG_ SBG_Velocity_Acc_N : 0|16@1+ (0.01,0) [0|655.35] "m.s-1" Vector__XXX
SG_ SBG_Velocity_Acc_E : 16|16@1+ (0.01,0) [0|655.35] "m.s-1" Vector__XXX
SG_ SBG_Velocity_Acc_D : 32|16@1+ (0.01,0) [0|655.35] "m.s-1" Vector__XXX

BO_ 1840 ELLIPSE_IMU_SHIP_MOTION_INFO: 8 Vector__XXX
SG_ SBG_Time_Stamp_SHIP_MOTION : 0|32@1+ (1E-006,0) [0|4294.967295] "s" Vector__XXX
SG_ SBG_Period_SHIP_MOTION : 32|16@1+ (0.01,0) [0|655.35] "s" Vector__XXX
SG_ SBG_Heave_Status_SHIP_MOTION : 48|16@1+ (1,0) [0|65535] "" Vector__XXX

BO_ 1841 ELLIPSE_IMU_SHIP_MOTION_0: 6 Vector__XXX
SG_ SBG_Surge_SHIP_MOTION : 0|16@1- (0.001,0) [-32.768|32.767] "m" Vector__XXX
SG_ SBG_Sway_SHIP_MOTION : 16|16@1- (0.001,0) [-32.768|32.767] "m" Vector__XXX
SG_ SBG_Heave_SHIP_MOTION : 32|16@1- (0.001,0) [-32.768|32.767] "m" Vector__XXX

BO_ 1842 ELLIPSE_IMU_SHIP_MOTION_1: 6 Vector__XXX
SG_ SBG_Accel_X_SHIP_MOTION_1 : 0|16@1- (0.01,0) [-327.68|327.67] "m.s-2" Vector__XXX
SG_ SBG_Accel_Y_SHIP_MOTION_1 : 16|16@1- (0.01,0) [-327.68|327.67] "m.s-2" Vector__XXX
SG_ SBG_Accel_Z_SHIP_MOTION_1 : 32|16@1- (0.01,0) [-327.68|327.67] "m.s-2" Vector__XXX

BO_ 1843 ELLIPSE_IMU_SHIP_MOTION_2: 6 Vector__XXX
SG_ SBG_Vel_X_SHIP_MOTION_2 : 0|16@1- (0.01,0) [-327.68|327.67] "m.s-1" Vector__XXX
SG_ SBG_Vel_Y_SHIP_MOTION_2 : 16|16@1- (0.01,0) [-327.68|327.67] "m.s-1" Vector__XXX
SG_ SBG_Vel_Z_SHIP_MOTION_2 : 32|16@1- (0.01,0) [-327.68|327.67] "m.s-1" Vector__XXX

BO_ 1856 ELLIPSE_IMU_MAG_0: 6 Vector__XXX
SG_ SBG_Time_Stamp_MAG0 : 0|32@1+ (1E-006,0) [0|4294.967295] "s" Vector__XXX
SG_ SBG_Mag_Status_MAG0 : 32|16@1+ (1,0) [0|65535] "" Vector__XXX

BO_ 1857 ELLIPSE_IMU_MAG_1: 6 Vector__XXX
SG_ SBG_Mag_X_MAG1 : 0|16@1- (0.001,0) [-32.768|32.767] "a.u." Vector__XXX
SG_ SBG_Mag_Y_MAG2 : 16|16@1- (0.001,0) [-32.768|32.767] "a.u." Vector__XXX
SG_ SBG_Mag_Z_MAG2 : 32|16@1- (0.001,0) [-32.768|32.767] "a.u." Vector__XXX

BO_ 1858 ELLIPSE_IMU_MAG_2: 6 Vector__XXX
SG_ SBG_Acc_X_MAG2 : 0|16@1- (0.01,0) [-327.68|327.67] "m.s-2" Vector__XXX
SG_ SBG_Acc_Y_MAG2 : 16|16@1- (0.01,0) [-327.68|327.67] "m.s-2" Vector__XXX
SG_ SBG_Acc_Z_MAG2 : 32|16@1- (0.01,0) [-327.68|327.67] "m.s-2" Vector__XXX

BO_ 1859 ELLIPSE_IMU_ODO_INFO: 6 Vector__XXX
SG_ SBG_Time_Stamp_ODO : 0|32@1+ (1E-006,0) [0|4294.967295] "s" Vector__XXX
SG_ SBG_Odo_Status : 32|16@1+ (1,0) [0|65535] "" Vector__XXX

BO_ 1860 ELLIPSE_IMU_ODO_VELOCITY: 4 Vector__XXX
SG_ SBG_Velocity_ODO : 0|32@1- (1,0) [-3.4E038|3.4E038] "m.s-1" Vector__XXX

BO_ 1861 ELLIPSE_IMU_PRESSURE_INFO: 5 Vector__XXX
SG_ SBG_Time_Stamp_PRESSURE : 0|32@1+ (1,0) [0|4294967295] "" Vector__XXX
SG_ SBG_Pressure_Status : 32|8@1+ (1,0) [0|255] "" Vector__XXX

BO_ 1862 ELLIPSE_IMU_PRESSURE_ALTITUDE: 8 Vector__XXX
SG_ SBG_Pressure_IMU : 0|32@1- (1,0) [-3.4E038|3.4E038] "1" Vector__XXX
SG_ SBG_Altitude_IMU : 32|32@1- (1,0) [-3.4E038|3.4E038] "1" Vector__XXX

BO_ 1872 ELLIPSE_IMU_GPS1_VEL_INFO: 8 Vector__XXX
SG_ SBG_Time_Stamp_GPS1_VEL : 0|32@1+ (1E-006,0) [0|4294.967295] "s" Vector__XXX
SG_ SBG_Gps_Vel_Status : 32|32@1+ (1,0) [0|4294967295] "" Vector__XXX

BO_ 1873 ELLIPSE_IMU_GPS1_VEL: 6 Vector__XXX
SG_ SBG_Vel_N : 0|16@1- (0.01,0) [-327.68|327.67] "m.s-1" Vector__XXX
SG_ SBG_Vel_E : 16|16@1- (0.01,0) [-327.68|327.67] "m.s-1" Vector__XXX
SG_ SBG_Vel_D : 32|16@1- (0.01,0) [-327.68|327.67] "m.s-1" Vector__XXX

BO_ 1874 ELLIPSE_IMU_GPS1_VEL_ACC: 6 Vector__XXX
SG_ SBG_Vel_Acc_N : 0|16@1+ (0.01,0) [0|655.35] "m.s-1" Vector__XXX
SG_ SBG_Vel_Acc_E : 16|16@1+ (0.01,0) [0|655.35] "m.s-1" Vector__XXX
SG_ SBG_Vel_Acc_D : 32|16@1+ (0.01,0) [0|655.35] "m.s-1" Vector__XXX

BO_ 1875 ELLIPSE_IMU_GPS1_COURSE: 4 Vector__XXX
SG_ SBG_Course : 0|16@1+ (0.01,0) [0|655.35] "'" Vector__XXX
SG_ SBG_Course_Acc : 16|16@1+ (0.01,0) [0|655.35] "'" Vector__XXX

BO_ 1876 ELLIPSE_IMU_GPS1_POS_INFO: 8 Vector__XXX
SG_ SBG_Time_Stamp_GPS1_POS : 0|32@1+ (1E-006,0) [0|4294.967295] "s" Vector__XXX
SG_ SBG_Gps_Pos_Status : 32|32@1+ (1,0) [0|4294967295] "" Vector__XXX

BO_ 1877 ELLIPSE_IMU_GPS1_POS: 8 Vector__XXX
SG_ SBG_Latitude_GPS1 : 0|32@1- (1E-007,0) [-214.7483648|214.7483647] "'" Vector__XXX
SG_ SBG_Longitude_GPS1 : 32|32@1- (1E-007,0) [-214.7483648|214.7483647] "'" Vector__XXX

BO_ 1878 ELLIPSE_IMU_GPS1_ALT: 8 Vector__XXX
SG_ SBG_Altitude_GPS1 : 0|32@1- (0.001,0) [-2147483.648|2147483.647] "m" Vector__XXX
SG_ SBG_Undulation_GPS1 : 32|16@1- (0.005,0) [-163.84|163.835] "m" Vector__XXX
SG_ SBG_Num_Sv_GPS1 : 48|8@1+ (1,0) [0|255] "" Vector__XXX
SG_ SBG_Diff_Corr_Age_GPS1 : 56|8@1+ (1,0) [0|255] "s" Vector__XXX

BO_ 1879 ELLIPSE_IMU_GPS1_POS_ACC: 8 Vector__XXX
SG_ SBG_Lat_Acc_GPS1 : 0|16@1+ (1,0) [0|65535] "m" Vector__XXX
SG_ SBG_Long_Acc_GPS1 : 16|16@1+ (1,0) [0|65535] "m" Vector__XXX
SG_ SBG_Alt_Acc_GPS1 : 32|16@1+ (1,0) [0|65535] "m" Vector__XXX
SG_ SBG_Base_Station_Id_GPS1 : 48|16@1+ (1,0) [0|65535] "" Vector__XXX

BO_ 1880 ELLIPSE_IMU_GPS1_HOT_INFO: 6 Vector__XXX
SG_ SBG_Time_Stamp_GPS1_HOT : 0|32@1+ (1E-006,0) [0|4294.967295] "s" Vector__XXX
SG_ SBG_Gps_Hdt_Status : 32|16@1+ (1,0) [0|65535] "" Vector__XXX

BO_ 1881 ELLIPSE_IMU_GPS1_HOT: 8 Vector__XXX
SG_ SBG_True_Heading_GPS1 : 0|16@1+ (1,0) [0|65535] "'" Vector__XXX
SG_ SBG_True_Heading_Acc_GPS1 : 16|16@1+ (1,0) [0|65535] "'" Vector__XXX
SG_ SBG_Pitch_GPS1 : 32|16@1- (1,0) [-32768|32767] "'" Vector__XXX
SG_ SBG_Pitch_Acc_GPS1 : 48|16@1+ (1,0) [0|65535] "'" Vector__XXX

BO_ 1888 ELLIPSE_IMU_EVENT_INFO_A: 6 Vector__XXX
SG_ SBG_Time_Stamp_EVENTA : 0|32@1+ (1E-006,0) [0|4294.967295] "s" Vector__XXX
SG_ SBG_Event_Status : 32|16@1+ (1,0) [0|65535] "" Vector__XXX

BO_ 1889 ELLIPSE_IMU_EVENT_TIME_A: 8 Vector__XXX
SG_ SBG_Time_Offset_0 : 0|16@1+ (1E-006,0) [0|0.065535] "s" Vector__XXX
SG_ SBG_Time_Offset_1 : 16|16@1+ (1E-006,0) [0|0.065535] "s" Vector__XXX
SG_ SBG_Time_Offset_2 : 32|16@1+ (1E-006,0) [0|0.065535] "s" Vector__XXX
SG_ SBG_Time_Offset_3 : 48|16@1+ (1E-006,0) [0|0.065535] "s" Vector__XXX

BO_ 1834 ELLIPSE_AUTOMOTIVE_DATA: 7 Vector__XXX
SG_ SBG_Auto_Angle_Track : 0|16@1- (0.0001,0) [-3.2768|3.2767] "rad" Vector__XXX
SG_ SBG_Auto_Angle_Slip : 16|16@1- (0.0001,0) [-3.2768|3.2767] "rad" Vector__XXX
SG_ SBG_Auto_Curvature_Radius : 32|16@1+ (0.01,0) [0|655.35] "m" Vector__XXX
SG_ SBG_Auto_Track_Valid : 48|1@1+ (1,0) [0|1] "" Vector__XXX
SG_ SBG_Auto_Slip_Valid : 49|1@1+ (1,0) [0|1] "" Vector__XXX
SG_ SBG_Auto_Curvature_Valid : 50|1@1+ (1,0) [0|1] "" Vector__XXX

BO_ 1320 BRUSA_Charger_Control: 7 Vector__XXX
SG_ Charger_Enable_Vector : 0|8@1+ (1,0) [0|255] "" Vector__XXX
SG_ Max_Mains_Current : 15|16@0+ (0.1,0) [0|6553.5] "A" Vector__XXX
SG_ Requested_Voltage : 31|16@0+ (0.1,0) [0|6553.5] "V" Vector__XXX
SG_ Requested_Current : 47|16@0+ (0.1,0) [0|6553.5] "A" Vector__XXX

BO_ 1312 BRUSA_Charger_Status: 8 Vector__XXX

BO_ 1313 BRUSA_Charger_Act_I: 8 Vector__XXX
SG_ Mains_Current : 7|16@0+ (0.01,0) [0|655.35] "A" Vector__XXX
SG_ Mains_Voltage : 23|16@0+ (0.1,0) [0|6553.5] "V" Vector__XXX
SG_ Batt_Voltage : 39|16@0+ (0.1,0) [0|6553.5] "V" Vector__XXX
SG_ Batt_Current : 55|16@0+ (0.01,0) [0|655.35] "A" Vector__XXX

BO_ 1315 BRUSA_Charger_Temp: 8 Vector__XXX
SG_ Power_Stage_Temp : 7|16@0+ (0.1,-4) [-4|6549.5] "C" Vector__XXX

BO_ 1316 BRUSA_Charger_Error: 5 Vector__XXX
SG_ Output_overvoltage : 7|1@1+ (1,0) [0|1] "" Vector__XXX
SG_ Mains_overvoltage_2 : 6|1@1+ (1,0) [0|1] "" Vector__XXX
SG_ Mains_overvoltage_1 : 5|1@1+ (1,0) [0|1] "" Vector__XXX
SG_ Short_circuit : 4|1@1+ (1,0) [0|1] "" Vector__XXX
SG_ Batt_out_implausible : 3|1@1+ (1,0) [0|1] "" Vector__XXX
SG_ Mains_volts_implausible : 2|1@1+ (1,0) [0|1] "" Vector__XXX
SG_ Output_fuse_defect : 1|1@1+ (1,0) [0|1] "" Vector__XXX
SG_ Mains_fuse_defect : 0|1@1+ (1,0) [0|1] "" Vector__XXX
SG_ Batt_polarity_wrong : 15|1@1+ (1,0) [0|1] "" Vector__XXX
SG_ Temp_sensor_defect_prim_cap : 14|1@1+ (1,0) [0|1] "" Vector__XXX
SG_ Temp_sensor_defect_prim_power : 13|1@1+ (1,0) [0|1] "" Vector__XXX
SG_ Temp_sensor_defect_diodes : 12|1@1+ (1,0) [0|1] "" Vector__XXX
SG_ Temp_sensor_defect_transformer : 11|1@1+ (1,0) [0|1] "" Vector__XXX
SG_ Temp_sensor_defect_ext1 : 10|1@1+ (1,0) [0|1] "" Vector__XXX
SG_ Temp_sensor_defect_ext2 : 9|1@1+ (1,0) [0|1] "" Vector__XXX
SG_ Temp_sensor_defect_ext3 : 8|1@1+ (1,0) [0|1] "" Vector__XXX
SG_ Flash_checksum_fail : 23|1@1+ (1,0) [0|1] "" Vector__XXX
SG_ NVSRAM_checksum_fail : 22|1@1+ (1,0) [0|1] "" Vector__XXX
SG_ Sys_EEPROM_checksum_fail : 21|1@1+ (1,0) [0|1] "" Vector__XXX
SG_ Pow_EEPROM_checksum_fail : 20|1@1+ (1,0) [0|1] "" Vector__XXX
SG_ Internal_watchdog_timeout : 19|1@1+ (1,0) [0|1] "" Vector__XXX
SG_ Initialization_error : 18|1@1+ (1,0) [0|1] "" Vector__XXX
SG_ CAN_timeout_300ms : 17|1@1+ (1,0) [0|1] "" Vector__XXX
SG_ CAN_off : 16|1@1+ (1,0) [0|1] "" Vector__XXX
SG_ CAN_tx_buf_more_than_127 : 31|1@1+ (1,0) [0|1] "" Vector__XXX
SG_ CAN_rx_buf_more_than_127 : 30|1@1+ (1,0) [0|1] "" Vector__XXX
SG_ Batt_temp_exceeded : 29|1@1+ (1,0) [0|1] "" Vector__XXX
SG_ Batt_volt_exceeded : 28|1@1+ (1,0) [0|1] "" Vector__XXX
SG_ Amp_hours_exceeded : 27|1@1+ (1,0) [0|1] "" Vector__XXX
SG_ Charge_time_exceeded : 26|1@1+ (1,0) [0|1] "" Vector__XXX
SG_ Low_mains_voltage : 39|1@1+ (1,0) [0|1] "" Vector__XXX
SG_ Low_batt_voltage : 38|1@1+ (1,0) [0|1] "" Vector__XXX
SG_ Internal_overtemp : 37|1@1+ (1,0) [0|1] "" Vector__XXX
SG_ Command_out_of_range : 36|1@1+ (1,0) [0|1] "" Vector__XXX
SG_ Ctrl_msg_inactive : 35|1@1+ (1,0) [0|1] "" Vector__XXX
SG_ LED_driver_defect : 33|1@1+ (1,0) [0|1] "" Vector__XXX
SG_ Save_charging_mode : 32|1@1+ (1,0) [0|1] "" Vector__XXX

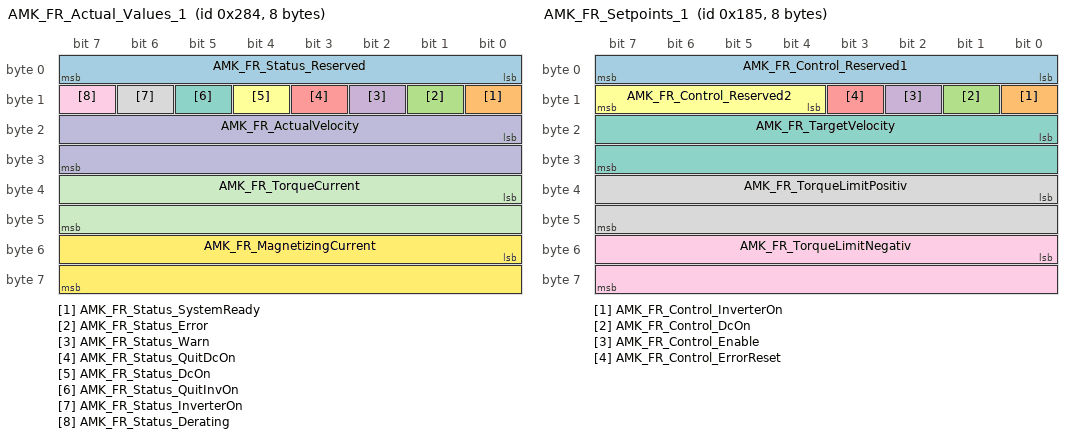
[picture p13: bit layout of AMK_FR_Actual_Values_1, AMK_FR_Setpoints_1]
BO_ 644 AMK_FR_Actual_Values_1: 8 Vector__XXX
SG_ AMK_FR_Status_Reserved : 0|8@1+ (1,0) [0|255] "" Vector__XXX
SG_ AMK_FR_Status_SystemReady : 8|1@1+ (1,0) [0|1] "" Vector__XXX
SG_ AMK_FR_Status_Error : 9|1@1+ (1,0) [0|1] "" Vector__XXX
SG_ AMK_FR_Status_Warn : 10|1@1+ (1,0) [0|1] "" Vector__XXX
SG_ AMK_FR_Status_QuitDcOn : 11|1@1+ (1,0) [0|1] "" Vector__XXX
SG_ AMK_FR_Status_DcOn : 12|1@1+ (1,0) [0|1] "" Vector__XXX
SG_ AMK_FR_Status_QuitInvOn : 13|1@1+ (1,0) [0|1] "" Vector__XXX
SG_ AMK_FR_Status_InverterOn : 14|1@1+ (1,0) [0|1] "" Vector__XXX
SG_ AMK_FR_Status_Derating : 15|1@1+ (1,0) [0|1] "" Vector__XXX
SG_ AMK_FR_ActualVelocity : 16|16@1- (1,0) [-32768|32767] "rpm" Vector__XXX
SG_ AMK_FR_TorqueCurrent : 32|16@1- (0.001701171875,0) [-55.744|55.742298828125] "Nm" Vector__XXX
SG_ AMK_FR_MagnetizingCurrent : 48|16@1- (0.001701171875,0) [-55.744|55.742298828125] "Nm" Vector__XXX

BO_ 646 AMK_FR_Actual_Values_2: 8 Vector__XXX
SG_ AMK_FR_TempMotor : 0|16@1- (0.1,0) [-3276.8|3276.7] "'C" Vector__XXX
SG_ AMK_FR_TempInverter : 16|16@1- (0.1,0) [-3276.8|3276.7] "'C" Vector__XXX
SG_ AMK_FR_ErrorInfo : 32|16@1+ (1,0) [0|65535] "" Vector__XXX
SG_ AMK_FR_TempIGBT : 48|16@1- (0.1,0) [-3276.8|3276.7] "'C" Vector__XXX

BO_ 389 AMK_FR_Setpoints_1: 8 Vector__XXX
SG_ AMK_FR_Control_Reserved1 : 0|8@1+ (1,0) [0|255] "" Vector__XXX
SG_ AMK_FR_Control_InverterOn : 8|1@1+ (1,0) [0|1] "" Vector__XXX
SG_ AMK_FR_Control_DcOn : 9|1@1+ (1,0) [0|1] "" Vector__XXX
SG_ AMK_FR_Control_Enable : 10|1@1+ (1,0) [0|1] "" Vector__XXX
SG_ AMK_FR_Control_ErrorReset : 11|1@1+ (1,0) [0|1] "" Vector__XXX
SG_ AMK_FR_Control_Reserved2 : 12|4@1+ (1,0) [0|15] "" Vector__XXX
SG_ AMK_FR_TargetVelocity : 16|16@1- (1,0) [-32768|32767] "rpm" Vector__XXX
SG_ AMK_FR_TorqueLimitPositiv : 32|16@1- (0.0098,0) [-321.1264|321.1166] "Nm" Vector__XXX
SG_ AMK_FR_TorqueLimitNegativ : 48|16@1- (0.0098,0) [-321.1264|321.1166] "Nm" Vector__XXX

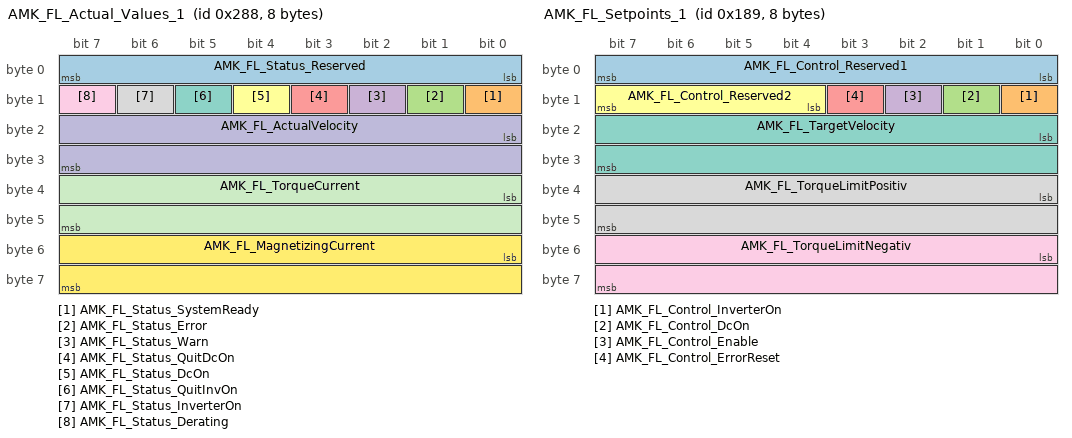
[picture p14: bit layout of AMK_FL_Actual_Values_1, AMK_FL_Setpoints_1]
BO_ 648 AMK_FL_Actual_Values_1: 8 Vector__XXX
SG_ AMK_FL_Status_Reserved : 0|8@1+ (1,0) [0|255] "" Vector__XXX
SG_ AMK_FL_Status_SystemReady : 8|1@1+ (1,0) [0|1] "" Vector__XXX
SG_ AMK_FL_Status_Error : 9|1@1+ (1,0) [0|1] "" Vector__XXX
SG_ AMK_FL_Status_Warn : 10|1@1+ (1,0) [0|1] "" Vector__XXX
SG_ AMK_FL_Status_QuitDcOn : 11|1@1+ (1,0) [0|1] "" Vector__XXX
SG_ AMK_FL_Status_DcOn : 12|1@1+ (1,0) [0|1] "" Vector__XXX
SG_ AMK_FL_Status_QuitInvOn : 13|1@1+ (1,0) [0|1] "" Vector__XXX
SG_ AMK_FL_Status_InverterOn : 14|1@1+ (1,0) [0|1] "" Vector__XXX
SG_ AMK_FL_Status_Derating : 15|1@1+ (1,0) [0|1] "" Vector__XXX
SG_ AMK_FL_ActualVelocity : 16|16@1- (1,0) [-32768|32767] "rpm" Vector__XXX
SG_ AMK_FL_TorqueCurrent : 32|16@1- (0.001701171875,0) [-55.744|55.742298828125] "Nm" Vector__XXX
SG_ AMK_FL_MagnetizingCurrent : 48|16@1- (0.001701171875,0) [-55.744|55.742298828125] "Nm" Vector__XXX

BO_ 650 AMK_FL_Actual_Values_2: 8 Vector__XXX
SG_ AMK_FL_TempMotor : 0|16@1- (0.1,0) [-3276.8|3276.7] "'C" Vector__XXX
SG_ AMK_FL_TempInverter : 16|16@1- (0.1,0) [-3276.8|3276.7] "'C" Vector__XXX
SG_ AMK_FL_ErrorInfo : 32|16@1+ (1,0) [0|65535] "" Vector__XXX
SG_ AMK_FL_TempIGBT : 48|16@1- (0.1,0) [-3276.8|3276.7] "'C" Vector__XXX

BO_ 393 AMK_FL_Setpoints_1: 8 Vector__XXX
SG_ AMK_FL_Control_Reserved1 : 0|8@1+ (1,0) [0|255] "" Vector__XXX
SG_ AMK_FL_Control_InverterOn : 8|1@1+ (1,0) [0|1] "" Vector__XXX
SG_ AMK_FL_Control_DcOn : 9|1@1+ (1,0) [0|1] "" Vector__XXX
SG_ AMK_FL_Control_Enable : 10|1@1+ (1,0) [0|1] "" Vector__XXX
SG_ AMK_FL_Control_ErrorReset : 11|1@1+ (1,0) [0|1] "" Vector__XXX
SG_ AMK_FL_Control_Reserved2 : 12|4@1+ (1,0) [0|15] "" Vector__XXX
SG_ AMK_FL_TargetVelocity : 16|16@1- (1,0) [-32768|32767] "rpm" Vector__XXX
SG_ AMK_FL_TorqueLimitPositiv : 32|16@1- (0.0098,0) [-321.1264|321.1166] "Nm" Vector__XXX
SG_ AMK_FL_TorqueLimitNegativ : 48|16@1- (0.0098,0) [-321.1264|321.1166] "Nm" Vector__XXX

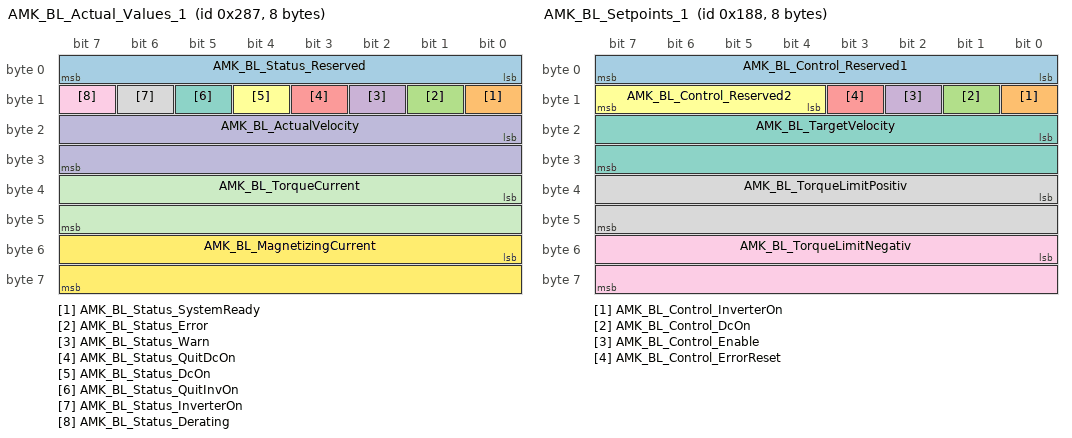
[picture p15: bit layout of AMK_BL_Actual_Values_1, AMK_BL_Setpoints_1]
BO_ 647 AMK_BL_Actual_Values_1: 8 Vector__XXX
SG_ AMK_BL_Status_Reserved : 0|8@1+ (1,0) [0|255] "" Vector__XXX
SG_ AMK_BL_Status_SystemReady : 8|1@1+ (1,0) [0|1] "" Vector__XXX
SG_ AMK_BL_Status_Error : 9|1@1+ (1,0) [0|1] "" Vector__XXX
SG_ AMK_BL_Status_Warn : 10|1@1+ (1,0) [0|1] "" Vector__XXX
SG_ AMK_BL_Status_QuitDcOn : 11|1@1+ (1,0) [0|1] "" Vector__XXX
SG_ AMK_BL_Status_DcOn : 12|1@1+ (1,0) [0|1] "" Vector__XXX
SG_ AMK_BL_Status_QuitInvOn : 13|1@1+ (1,0) [0|1] "" Vector__XXX
SG_ AMK_BL_Status_InverterOn : 14|1@1+ (1,0) [0|1] "" Vector__XXX
SG_ AMK_BL_Status_Derating : 15|1@1+ (1,0) [0|1] "" Vector__XXX
SG_ AMK_BL_ActualVelocity : 16|16@1- (1,0) [-32768|32767] "rpm" Vector__XXX
SG_ AMK_BL_TorqueCurrent : 32|16@1- (0.001701171875,0) [-55.744|55.742298828125] "Nm" Vector__XXX
SG_ AMK_BL_MagnetizingCurrent : 48|16@1- (0.001701171875,0) [-55.744|55.742298828125] "Nm" Vector__XXX

BO_ 649 AMK_BL_Actual_Values_2: 8 Vector__XXX
SG_ AMK_BL_TempMotor : 0|16@1- (0.1,0) [-3276.8|3276.7] "'C" Vector__XXX
SG_ AMK_BL_TempInverter : 16|16@1- (0.1,0) [-3276.8|3276.7] "'C" Vector__XXX
SG_ AMK_BL_ErrorInfo : 32|16@1+ (1,0) [0|65535] "" Vector__XXX
SG_ AMK_BL_TempIGBT : 48|16@1- (0.1,0) [-3276.8|3276.7] "'C" Vector__XXX

BO_ 392 AMK_BL_Setpoints_1: 8 Vector__XXX
SG_ AMK_BL_Control_Reserved1 : 0|8@1+ (1,0) [0|255] "" Vector__XXX
SG_ AMK_BL_Control_InverterOn : 8|1@1+ (1,0) [0|1] "" Vector__XXX
SG_ AMK_BL_Control_DcOn : 9|1@1+ (1,0) [0|1] "" Vector__XXX
SG_ AMK_BL_Control_Enable : 10|1@1+ (1,0) [0|1] "" Vector__XXX
SG_ AMK_BL_Control_ErrorReset : 11|1@1+ (1,0) [0|1] "" Vector__XXX
SG_ AMK_BL_Control_Reserved2 : 12|4@1+ (1,0) [0|15] "" Vector__XXX
SG_ AMK_BL_TargetVelocity : 16|16@1- (1,0) [-32768|32767] "rpm" Vector__XXX
SG_ AMK_BL_TorqueLimitPositiv : 32|16@1- (0.0098,0) [-321.1264|321.1166] "Nm" Vector__XXX
SG_ AMK_BL_TorqueLimitNegativ : 48|16@1- (0.0098,0) [-321.1264|321.1166] "Nm" Vector__XXX

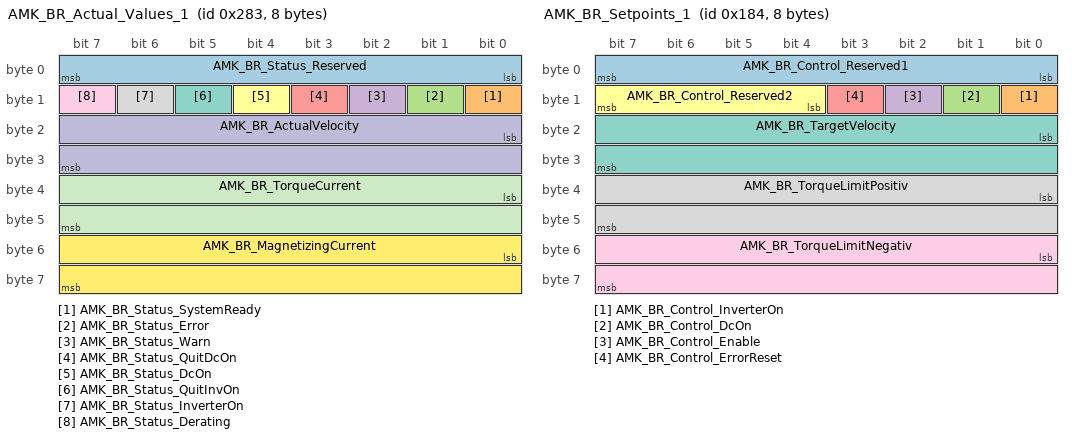
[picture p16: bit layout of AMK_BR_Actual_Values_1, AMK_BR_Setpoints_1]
BO_ 643 AMK_BR_Actual_Values_1: 8 Vector__XXX
SG_ AMK_BR_Status_Reserved : 0|8@1+ (1,0) [0|255] "" Vector__XXX
SG_ AMK_BR_Status_SystemReady : 8|1@1+ (1,0) [0|1] "" Vector__XXX
SG_ AMK_BR_Status_Error : 9|1@1+ (1,0) [0|1] "" Vector__XXX
SG_ AMK_BR_Status_Warn : 10|1@1+ (1,0) [0|1] "" Vector__XXX
SG_ AMK_BR_Status_QuitDcOn : 11|1@1+ (1,0) [0|1] "" Vector__XXX
SG_ AMK_BR_Status_DcOn : 12|1@1+ (1,0) [0|1] "" Vector__XXX
SG_ AMK_BR_Status_QuitInvOn : 13|1@1+ (1,0) [0|1] "" Vector__XXX
SG_ AMK_BR_Status_InverterOn : 14|1@1+ (1,0) [0|1] "" Vector__XXX
SG_ AMK_BR_Status_Derating : 15|1@1+ (1,0) [0|1] "" Vector__XXX
SG_ AMK_BR_ActualVelocity : 16|16@1- (1,0) [-32768|32767] "rpm" Vector__XXX
SG_ AMK_BR_TorqueCurrent : 32|16@1- (0.001701171875,0) [-55.744|55.742298828125] "Nm" Vector__XXX
SG_ AMK_BR_MagnetizingCurrent : 48|16@1- (0.001701171875,0) [-55.744|55.742298828125] "Nm" Vector__XXX

BO_ 645 AMK_BR_Actual_Values_2: 8 Vector__XXX
SG_ AMK_BR_TempMotor : 0|16@1- (0.1,0) [-3276.8|3276.7] "'C" Vector__XXX
SG_ AMK_BR_TempInverter : 16|16@1- (0.1,0) [-3276.8|3276.7] "'C" Vector__XXX
SG_ AMK_BR_ErrorInfo : 32|16@1+ (1,0) [0|65535] "" Vector__XXX
SG_ AMK_BR_TempIGBT : 48|16@1- (0.1,0) [-3276.8|3276.7] "'C" Vector__XXX

BO_ 388 AMK_BR_Setpoints_1: 8 Vector__XXX
SG_ AMK_BR_Control_Reserved1 : 0|8@1+ (1,0) [0|255] "" Vector__XXX
SG_ AMK_BR_Control_InverterOn : 8|1@1+ (1,0) [0|1] "" Vector__XXX
SG_ AMK_BR_Control_DcOn : 9|1@1+ (1,0) [0|1] "" Vector__XXX
SG_ AMK_BR_Control_Enable : 10|1@1+ (1,0) [0|1] "" Vector__XXX
SG_ AMK_BR_Control_ErrorReset : 11|1@1+ (1,0) [0|1] "" Vector__XXX
SG_ AMK_BR_Control_Reserved2 : 12|4@1+ (1,0) [0|15] "" Vector__XXX
SG_ AMK_BR_TargetVelocity : 16|16@1- (1,0) [-32768|32767] "rpm" Vector__XXX
SG_ AMK_BR_TorqueLimitPositiv : 32|16@1- (0.0098,0) [-321.1264|321.1166] "Nm" Vector__XXX
SG_ AMK_BR_TorqueLimitNegativ : 48|16@1- (0.0098,0) [-321.1264|321.1166] "Nm" Vector__XXX

BO_ 2021 CDC_CONTROLS_PID: 8 Vector__XXX
SG_ controls_current_yaw_rate : 0|16@1- (0.01,0) [-327.68|327.67] "rad.s-1" Vector__XXX
SG_ controls_target_yaw_rate : 16|16@1- (0.01,0) [-327.68|327.67] "rad.s-1" Vector__XXX
SG_ controls_pid : 32|32@1- (0.01,0) [-3.4E036|3.4E036] "" Vector__XXX

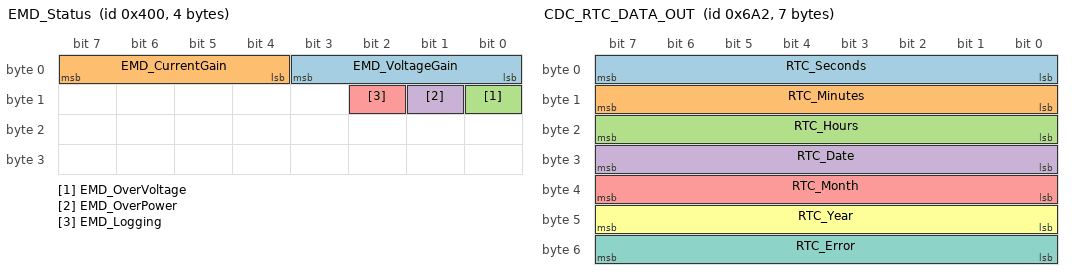
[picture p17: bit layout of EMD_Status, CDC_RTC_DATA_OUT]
BO_ 1024 EMD_Status: 4 Vector__XXX
SG_ EMD_VoltageGain : 3|4@0+ (1,0) [0|15] "" Vector__XXX
SG_ EMD_CurrentGain : 7|4@0+ (1,0) [0|15] "" Vector__XXX
SG_ EMD_OverVoltage : 8|1@0+ (1,0) [0|1] "bool" Vector__XXX
SG_ EMD_OverPower : 9|1@0+ (1,0) [0|1] "bool" Vector__XXX
SG_ EMD_Logging : 10|1@0+ (1,0) [0|1] "bool" Vector__XXX

BO_ 2023 EMD_Reserved1: 8 Vector__XXX

BO_ 2031 EMD_Reserved2: 8 Vector__XXX

BO_ 2000 IZZE_Loadcell_FR: 8 Vector__XXX
SG_ FR_Differential_Voltage : 7|16@0- (1,0) [-32768|32767] "uV" Vector__XXX
SG_ FR_Calibrated_Output : 23|16@0- (0.1,0) [-3276.8|3276.7] "N" Vector__XXX
SG_ FR_Internal_Temp : 39|16@0- (0.1,0) [-3276.8|3276.7] "c" Vector__XXX
SG_ FR_Opt_External_Temp : 55|16@0- (0.1,0) [-3276.8|3276.7] "c" Vector__XXX

BO_ 2002 IZZE_Loadcell_RR: 8 Vector__XXX
SG_ RR_Differential_Voltage : 7|16@0- (1,0) [-32768|32767] "uV" Vector__XXX
SG_ RR_Calibrated_Output : 23|16@0- (0.1,0) [-3276.8|3276.7] "N" Vector__XXX
SG_ RR_Internal_Temp : 39|16@0- (0.1,0) [-3276.8|3276.7] "c" Vector__XXX
SG_ RR_Opt_External_Temp : 55|16@0- (0.1,0) [-3276.8|3276.7] "c" Vector__XXX

BO_ 2003 IZZE_Loadcell_FL: 8 Vector__XXX
SG_ FL_Differential_Voltage : 7|16@0- (1,0) [-32768|32767] "uV" Vector__XXX
SG_ FL_Calibrated_Output : 23|16@0- (0.1,0) [-3276.8|3276.7] "N" Vector__XXX
SG_ FL_Internal_Temp : 39|16@0- (0.1,0) [-3276.8|3276.7] "c" Vector__XXX
SG_ FL_Opt_External_Temp : 55|16@0- (0.1,0) [-3276.8|3276.7] "c" Vector__XXX

BO_ 2001 IZZE_Loadcell_RL: 8 Vector__XXX
SG_ RL_Differential_Voltage : 7|16@0- (1,0) [-32768|32767] "uV" Vector__XXX
SG_ RL_Calibrated_Output : 23|16@0- (0.1,0) [-3276.8|3276.7] "N" Vector__XXX
SG_ RL_Internal_Temp : 39|16@0- (0.1,0) [-3276.8|3276.7] "c" Vector__XXX
SG_ RL_Opt_External_Temp : 55|16@0- (0.1,0) [-3276.8|3276.7] "c" Vector__XXX

BO_ 1952 DCM_Configure: 8 Vector__XXX
SG_ frequency : 0|32@1+ (1,0) [400|480] "MHz" Vector__XXX
SG_ padding : 32|16@1+ (1,0) [0|1] "" Vector__XXX
SG_ volume : 48|8@1+ (1,0) [0|7] "" Vector__XXX
SG_ squelch : 56|8@1+ (1,0) [0|8] "" Vector__XXX

BO_ 1698 CDC_RTC_DATA_OUT: 7 Vector__XXX
SG_ RTC_Seconds : 0|8@1+ (1,0) [0|255] "seconds" Vector__XXX
SG_ RTC_Minutes : 8|8@1+ (1,0) [0|255] "minutes" Vector__XXX
SG_ RTC_Hours : 16|8@1+ (1,0) [0|255] "hours" Vector__XXX
SG_ RTC_Date : 24|8@1+ (1,0) [0|255] "day" Vector__XXX
SG_ RTC_Month : 32|8@1+ (1,0) [0|255] "month" Vector__XXX
SG_ RTC_Year : 40|8@1+ (1,0) [0|255] "year" Vector__XXX
SG_ RTC_Error : 48|8@1+ (1,0) [0|255] "" Vector__XXX

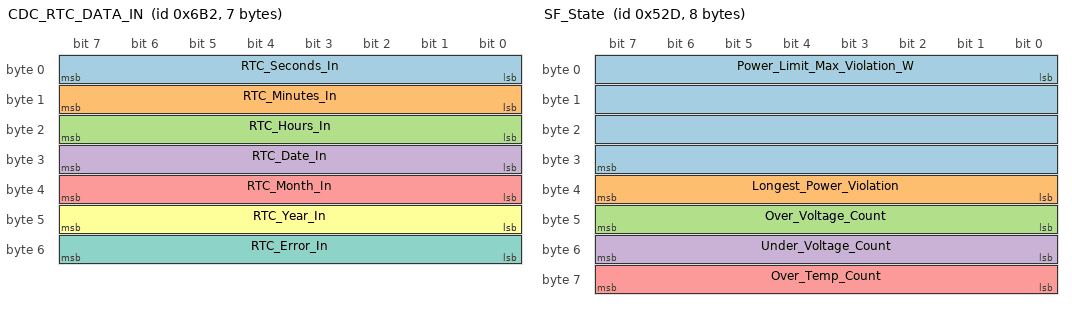
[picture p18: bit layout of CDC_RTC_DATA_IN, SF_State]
BO_ 1714 CDC_RTC_DATA_IN: 7 Vector__XXX
SG_ RTC_Seconds_In : 0|8@1+ (1,0) [0|255] "seconds" Vector__XXX
SG_ RTC_Minutes_In : 8|8@1+ (1,0) [0|255] "minutes" Vector__XXX
SG_ RTC_Hours_In : 16|8@1+ (1,0) [0|255] "hours" Vector__XXX
SG_ RTC_Date_In : 24|8@1+ (1,0) [0|255] "day" Vector__XXX
SG_ RTC_Month_In : 32|8@1+ (1,0) [0|255] "month" Vector__XXX
SG_ RTC_Year_In : 40|8@1+ (1,0) [0|255] "year" Vector__XXX
SG_ RTC_Error_In : 48|8@1+ (1,0) [0|255] "" Vector__XXX

BO_ 1730 CDC_ODOMETER: 4 Vector__XXX
SG_ CDC_Odometer : 0|32@1- (1,0) [-3.4E038|3.4E038] "km" Vector__XXX

BO_ 1324 CDC_DrsState: 4 Vector__XXX
SG_ drsState : 0|8@1+ (1,0) [0|255] "" Vector__XXX
SG_ drsAngle : 8|8@1+ (1,0) [0|255] "" Vector__XXX
SG_ drsPwmLeft : 16|8@1+ (1,0) [0|255] "" Vector__XXX
SG_ drsPwmRight : 24|8@1+ (1,0) [0|255] "" Vector__XXX

BO_ 1325 SF_State: 8 Vector__XXX
SG_ Power_Limit_Max_Violation_W : 0|32@1- (1,0) [-3.4E038|3.4E038] "W" Vector__XXX
SG_ Longest_Power_Violation : 32|8@1+ (1,0) [0|255] "" Vector__XXX
SG_ Over_Voltage_Count : 40|8@1+ (1,0) [0|255] "" Vector__XXX
SG_ Under_Voltage_Count : 48|8@1+ (1,0) [0|255] "" Vector__XXX
SG_ Over_Temp_Count : 56|8@1+ (1,0) [0|255] "" Vector__XXX

BO_ 1326 CDC_Motor_Power: 8 Vector__XXX
SG_ motor_power_FL : 0|16@1+ (1,0) [0|65535] "" Vector__XXX
SG_ motor_power_FR : 16|16@1+ (1,0) [0|65535] "" Vector__XXX
SG_ motor_power_RL : 32|16@1+ (1,0) [0|65535] "" Vector__XXX
SG_ motor_power_RR : 48|16@1+ (1,0) [0|65535] "" Vector__XXX

BO_ 2024 CDC_Front_Slip_Ratios: 8 Vector__XXX
SG_ slipRatio_FL : 0|32@1- (1,0) [-3.4E038|3.4E038] "" Vector__XXX
SG_ slipRatio_FR : 32|32@1- (1,0) [-3.4E038|3.4E038] "" Vector__XXX

BO_ 2025 CDC_Rear_Slip_Ratios: 8 Vector__XXX
SG_ slipRatio_RL : 0|32@1- (1,0) [-3.4E038|3.4E038] "" Vector__XXX
SG_ slipRatio_RR : 32|32@1- (1,0) [-3.4E038|3.4E038] "" Vector__XXX

BO_ 2026 CDC_Front_Velocity_Setpoints: 8 Vector__XXX
SG_ setPoint_FL : 0|32@1- (1,0) [-3.4E038|3.4E038] "" Vector__XXX
SG_ setPoint_FR : 32|32@1- (1,0) [-3.4E038|3.4E038] "" Vector__XXX

BO_ 2027 CDC_Rear_Velocity_Setpoints: 8 Vector__XXX
SG_ setPoint_RL : 0|32@1- (1,0) [-3.4E038|3.4E038] "" Vector__XXX
SG_ setPoint_RR : 32|32@1- (1,0) [-3.4E038|3.4E038] "" Vector__XXX

BO_ 2028 CDC_Front_Whl_Velocity_Calc: 8 Vector__XXX
SG_ vel_calc_FL : 0|32@1- (1,0) [-3.4E038|3.4E038] "" Vector__XXX
SG_ vel_calc_FR : 32|32@1- (1,0) [-3.4E038|3.4E038] "" Vector__XXX

BO_ 2029 CDC_Rear_Whl_Velocity_Calc: 8 Vector__XXX
SG_ vel_calc_RL : 0|32@1- (1,0) [-3.4E038|3.4E038] "" Vector__XXX
SG_ vel_calc_RR : 32|32@1- (1,0) [-3.4E038|3.4E038] "" Vector__XXX

BO_ 1536 DIM_Config0_Drv0: 4 Vector__XXX
SG_ DIM_config0_drv0_config_val_1 : 0|8@1+ (1,0) [0|255] "" Vector__XXX
SG_ DIM_config0_drv0_config_val_2 : 8|8@1+ (1,0) [0|255] "" Vector__XXX
SG_ DIM_config0_drv0_config_val_3 : 16|8@1+ (1,0) [0|255] "" Vector__XXX
SG_ DIM_config0_drv0_config_val_4 : 24|8@1+ (1,0) [0|255] "" Vector__XXX

BO_ 1537 DIM_Config1_Drv0: 4 Vector__XXX
SG_ DIM_config1_drv0_config_val_1 : 0|8@1+ (1,0) [0|255] "" Vector__XXX
SG_ DIM_config1_drv0_config_val_2 : 8|8@1+ (1,0) [0|255] "" Vector__XXX
SG_ DIM_config1_drv0_config_val_3 : 16|8@1+ (1,0) [0|255] "" Vector__XXX
SG_ DIM_config1_drv0_config_val_4 : 24|8@1+ (1,0) [0|255] "" Vector__XXX

BO_ 1538 DIM_Config2_Drv0: 4 Vector__XXX
SG_ DIM_config2_drv0_config_val_1 : 0|8@1+ (1,0) [0|255] "" Vector__XXX
SG_ DIM_config2_drv0_config_val_2 : 8|8@1+ (1,0) [0|255] "" Vector__XXX
SG_ DIM_config2_drv0_config_val_3 : 16|8@1+ (1,0) [0|255] "" Vector__XXX
SG_ DIM_config2_drv0_config_val_4 : 24|8@1+ (1,0) [0|255] "" Vector__XXX

BO_ 1539 DIM_Config3_Drv0: 4 Vector__XXX
SG_ DIM_config3_drv0_config_val_1 : 0|8@1+ (1,0) [0|255] "" Vector__XXX
SG_ DIM_config3_drv0_config_val_2 : 8|8@1+ (1,0) [0|255] "" Vector__XXX
SG_ DIM_config3_drv0_config_val_3 : 16|8@1+ (1,0) [0|255] "" Vector__XXX
SG_ DIM_config3_drv0_config_val_4 : 24|8@1+ (1,0) [0|255] "" Vector__XXX

BO_ 1540 CDC_Config0_Drv0: 4 Vector__XXX
SG_ CDC_config0_drv0_config_val_1 : 0|8@1+ (1,0) [0|255] "" Vector__XXX
SG_ CDC_config0_drv0_config_val_2 : 8|8@1+ (1,0) [0|255] "" Vector__XXX
SG_ CDC_config0_drv0_config_val_3 : 16|8@1+ (1,0) [0|255] "" Vector__XXX
SG_ CDC_config0_drv0_config_val_4 : 24|8@1+ (1,0) [0|255] "" Vector__XXX

BO_ 1541 CDC_Config1_Drv0: 4 Vector__XXX
SG_ CDC_config1_drv0_config_val_1 : 0|8@1+ (1,0) [0|255] "" Vector__XXX
SG_ CDC_config1_drv0_config_val_2 : 8|8@1+ (1,0) [0|255] "" Vector__XXX
SG_ CDC_config1_drv0_config_val_3 : 16|8@1+ (1,0) [0|255] "" Vector__XXX
SG_ CDC_config1_drv0_config_val_4 : 24|8@1+ (1,0) [0|255] "" Vector__XXX

BO_ 1542 CDC_Config2_Drv0: 4 Vector__XXX
SG_ CDC_config2_drv0_config_val_1 : 0|8@1+ (1,0) [0|255] "" Vector__XXX
SG_ CDC_config2_drv0_config_val_2 : 8|8@1+ (1,0) [0|255] "" Vector__XXX
SG_ CDC_config2_drv0_config_val_3 : 16|8@1+ (1,0) [0|255] "" Vector__XXX
SG_ CDC_config2_drv0_config_val_4 : 24|8@1+ (1,0) [0|255] "" Vector__XXX

BO_ 1543 CDC_Config3_Drv0: 4 Vector__XXX
SG_ CDC_config3_drv0_config_val_1 : 0|8@1+ (1,0) [0|255] "" Vector__XXX
SG_ CDC_config3_drv0_config_val_2 : 8|8@1+ (1,0) [0|255] "" Vector__XXX
SG_ CDC_config3_drv0_config_val_3 : 16|8@1+ (1,0) [0|255] "" Vector__XXX
SG_ CDC_config3_drv0_config_val_4 : 24|8@1+ (1,0) [0|255] "" Vector__XXX

BO_ 1544 DIM_Config0_Drv1: 4 Vector__XXX
SG_ DIM_config0_drv1_config_val_1 : 0|8@1+ (1,0) [0|255] "" Vector__XXX
SG_ DIM_config0_drv1_config_val_2 : 8|8@1+ (1,0) [0|255] "" Vector__XXX
SG_ DIM_config0_drv1_config_val_3 : 16|8@1+ (1,0) [0|255] "" Vector__XXX
SG_ DIM_config0_drv1_config_val_4 : 24|8@1+ (1,0) [0|255] "" Vector__XXX

BO_ 1545 DIM_Config1_Drv1: 4 Vector__XXX
SG_ DIM_config1_drv1_config_val_1 : 0|8@1+ (1,0) [0|255] "" Vector__XXX
SG_ DIM_config1_drv1_config_val_2 : 8|8@1+ (1,0) [0|255] "" Vector__XXX
SG_ DIM_config1_drv1_config_val_3 : 16|8@1+ (1,0) [0|255] "" Vector__XXX
SG_ DIM_config1_drv1_config_val_4 : 24|8@1+ (1,0) [0|255] "" Vector__XXX

BO_ 1546 DIM_Config2_Drv1: 4 Vector__XXX
SG_ DIM_config2_drv1_config_val_1 : 0|8@1+ (1,0) [0|255] "" Vector__XXX
SG_ DIM_config2_drv1_config_val_2 : 8|8@1+ (1,0) [0|255] "" Vector__XXX
SG_ DIM_config2_drv1_config_val_3 : 16|8@1+ (1,0) [0|255] "" Vector__XXX
SG_ DIM_config2_drv1_config_val_4 : 24|8@1+ (1,0) [0|255] "" Vector__XXX

BO_ 1547 DIM_Config3_Drv1: 4 Vector__XXX
SG_ DIM_config3_drv1_config_val_1 : 0|8@1+ (1,0) [0|255] "" Vector__XXX
SG_ DIM_config3_drv1_config_val_2 : 8|8@1+ (1,0) [0|255] "" Vector__XXX
SG_ DIM_config3_drv1_config_val_3 : 16|8@1+ (1,0) [0|255] "" Vector__XXX
SG_ DIM_config3_drv1_config_val_4 : 24|8@1+ (1,0) [0|255] "" Vector__XXX

BO_ 1548 CDC_Config0_Drv1: 4 Vector__XXX
SG_ CDC_config0_drv1_config_val_1 : 0|8@1+ (1,0) [0|255] "" Vector__XXX
SG_ CDC_config0_drv1_config_val_2 : 8|8@1+ (1,0) [0|255] "" Vector__XXX
SG_ CDC_config0_drv1_config_val_3 : 16|8@1+ (1,0) [0|255] "" Vector__XXX
SG_ CDC_config0_drv1_config_val_4 : 24|8@1+ (1,0) [0|255] "" Vector__XXX

BO_ 1549 CDC_Config1_Drv1: 4 Vector__XXX
SG_ CDC_config1_drv1_config_val_1 : 0|8@1+ (1,0) [0|255] "" Vector__XXX
SG_ CDC_config1_drv1_config_val_2 : 8|8@1+ (1,0) [0|255] "" Vector__XXX
SG_ CDC_config1_drv1_config_val_3 : 16|8@1+ (1,0) [0|255] "" Vector__XXX
SG_ CDC_config1_drv1_config_val_4 : 24|8@1+ (1,0) [0|255] "" Vector__XXX

BO_ 1550 CDC_Config2_Drv1: 4 Vector__XXX
SG_ CDC_config2_drv1_config_val_1 : 0|8@1+ (1,0) [0|255] "" Vector__XXX
SG_ CDC_config2_drv1_config_val_2 : 8|8@1+ (1,0) [0|255] "" Vector__XXX
SG_ CDC_config2_drv1_config_val_3 : 16|8@1+ (1,0) [0|255] "" Vector__XXX
SG_ CDC_config2_drv1_config_val_4 : 24|8@1+ (1,0) [0|255] "" Vector__XXX

BO_ 1551 CDC_Config3_Drv1: 4 Vector__XXX
SG_ CDC_config3_drv1_config_val_1 : 0|8@1+ (1,0) [0|255] "" Vector__XXX
SG_ CDC_config3_drv1_config_val_2 : 8|8@1+ (1,0) [0|255] "" Vector__XXX
SG_ CDC_config3_drv1_config_val_3 : 16|8@1+ (1,0) [0|255] "" Vector__XXX
SG_ CDC_config3_drv1_config_val_4 : 24|8@1+ (1,0) [0|255] "" Vector__XXX

BO_ 1552 DIM_Config0_Drv2: 4 Vector__XXX
SG_ DIM_config1_drv2_config_val_1 : 0|8@1+ (1,0) [0|255] "" Vector__XXX
SG_ DIM_config1_drv2_config_val_2 : 8|8@1+ (1,0) [0|255] "" Vector__XXX
SG_ DIM_config1_drv2_config_val_3 : 16|8@1+ (1,0) [0|255] "" Vector__XXX
SG_ DIM_config1_drv2_config_val_4 : 24|8@1+ (1,0) [0|255] "" Vector__XXX

BO_ 1554 DIM_Config2_Drv2: 4 Vector__XXX
SG_ DIM_config2_drv2_config_val_1 : 0|8@1+ (1,0) [0|255] "" Vector__XXX
SG_ DIM_config2_drv2_config_val_2 : 8|8@1+ (1,0) [0|255] "" Vector__XXX
SG_ DIM_config2_drv2_config_val_3 : 16|8@1+ (1,0) [0|255] "" Vector__XXX
SG_ DIM_config2_drv2_config_val_4 : 24|8@1+ (1,0) [0|255] "" Vector__XXX

BO_ 1555 DIM_Config3_Drv2: 4 Vector__XXX
SG_ DIM_config3_drv2_config_val_1 : 0|8@1+ (1,0) [0|255] "" Vector__XXX
SG_ DIM_config3_drv2_config_val_2 : 8|8@1+ (1,0) [0|255] "" Vector__XXX
SG_ DIM_config3_drv2_config_val_3 : 16|8@1+ (1,0) [0|255] "" Vector__XXX
SG_ DIM_config3_drv2_config_val_4 : 24|8@1+ (1,0) [0|255] "" Vector__XXX

BO_ 1556 CDC_Config0_Drv2: 4 Vector__XXX
SG_ CDC_config0_drv2_config_val_1 : 0|8@1+ (1,0) [0|255] "" Vector__XXX
SG_ CDC_config0_drv2_config_val_2 : 8|8@1+ (1,0) [0|255] "" Vector__XXX
SG_ CDC_config0_drv2_config_val_3 : 16|8@1+ (1,0) [0|255] "" Vector__XXX
SG_ CDC_config0_drv2_config_val_4 : 24|8@1+ (1,0) [0|255] "" Vector__XXX

BO_ 1557 CDC_Config1_Drv2: 4 Vector__XXX
SG_ CDC_config1_drv2_config_val_1 : 0|8@1+ (1,0) [0|255] "" Vector__XXX
SG_ CDC_config1_drv2_config_val_2 : 8|8@1+ (1,0) [0|255] "" Vector__XXX
SG_ CDC_config1_drv2_config_val_3 : 16|8@1+ (1,0) [0|255] "" Vector__XXX
SG_ CDC_config1_drv2_config_val_4 : 24|8@1+ (1,0) [0|255] "" Vector__XXX

BO_ 1558 CDC_Config2_Drv2: 4 Vector__XXX
SG_ CDC_config2_drv2_config_val_1 : 0|8@1+ (1,0) [0|255] "" Vector__XXX
SG_ CDC_config2_drv2_config_val_2 : 8|8@1+ (1,0) [0|255] "" Vector__XXX
SG_ CDC_config2_drv2_config_val_3 : 16|8@1+ (1,0) [0|255] "" Vector__XXX
SG_ CDC_config2_drv2_config_val_4 : 24|8@1+ (1,0) [0|255] "" Vector__XXX

BO_ 1559 CDC_Config3_Drv2: 4 Vector__XXX
SG_ CDC_config3_drv2_config_val_1 : 0|8@1+ (1,0) [0|255] "" Vector__XXX
SG_ CDC_config3_drv2_config_val_2 : 8|8@1+ (1,0) [0|255] "" Vector__XXX
SG_ CDC_config3_drv2_config_val_3 : 16|8@1+ (1,0) [0|255] "" Vector__XXX
SG_ CDC_config3_drv2_config_val_4 : 24|8@1+ (1,0) [0|255] "" Vector__XXX

BO_ 1560 DIM_Config0_Drv3: 4 Vector__XXX
SG_ DIM_config0_drv3_config_val_1 : 0|8@1+ (1,0) [0|255] "" Vector__XXX
SG_ DIM_config0_drv3_config_val_2 : 8|8@1+ (1,0) [0|255] "" Vector__XXX
SG_ DIM_config0_drv3_config_val_3 : 16|8@1+ (1,0) [0|255] "" Vector__XXX
SG_ DIM_config0_drv3_config_val_4 : 24|8@1+ (1,0) [0|255] "" Vector__XXX

BO_ 1561 DIM_Config1_Drv3: 4 Vector__XXX
SG_ DIM_config1_drv3_config_val_1 : 0|8@1+ (1,0) [0|255] "" Vector__XXX
SG_ DIM_config1_drv3_config_val_2 : 8|8@1+ (1,0) [0|255] "" Vector__XXX
SG_ DIM_config1_drv3_config_val_3 : 16|8@1+ (1,0) [0|255] "" Vector__XXX
SG_ DIM_config1_drv3_config_val_4 : 24|8@1+ (1,0) [0|255] "" Vector__XXX

BO_ 1562 DIM_Config2_Drv3: 4 Vector__XXX
SG_ DIM_config2_drv3_config_val_1 : 0|8@1+ (1,0) [0|255] "" Vector__XXX
SG_ DIM_config2_drv3_config_val_2 : 8|8@1+ (1,0) [0|255] "" Vector__XXX
SG_ DIM_config2_drv3_config_val_3 : 16|8@1+ (1,0) [0|255] "" Vector__XXX
SG_ DIM_config2_drv3_config_val_4 : 24|8@1+ (1,0) [0|255] "" Vector__XXX

BO_ 1563 DIM_Config3_Drv3: 4 Vector__XXX
SG_ DIM_config3_drv3_config_val_1 : 0|8@1+ (1,0) [0|255] "" Vector__XXX
SG_ DIM_config3_drv3_config_val_2 : 8|8@1+ (1,0) [0|255] "" Vector__XXX
SG_ DIM_config3_drv3_config_val_3 : 16|8@1+ (1,0) [0|255] "" Vector__XXX
SG_ DIM_config3_drv3_config_val_4 : 24|8@1+ (1,0) [0|255] "" Vector__XXX

BO_ 1564 CDC_Config0_Drv3: 4 Vector__XXX
SG_ CDC_config0_drv3_config_val_1 : 0|8@1+ (1,0) [0|255] "" Vector__XXX
SG_ CDC_config0_drv3_config_val_2 : 8|8@1+ (1,0) [0|255] "" Vector__XXX
SG_ CDC_config0_drv3_config_val_3 : 16|8@1+ (1,0) [0|255] "" Vector__XXX
SG_ CDC_config0_drv3_config_val_4 : 24|8@1+ (1,0) [0|255] "" Vector__XXX

BO_ 1565 CDC_Config1_Drv3: 4 Vector__XXX
SG_ CDC_config1_drv3_config_val_1 : 0|8@1+ (1,0) [0|255] "" Vector__XXX
SG_ CDC_config1_drv3_config_val_2 : 8|8@1+ (1,0) [0|255] "" Vector__XXX
SG_ CDC_config1_drv3_config_val_3 : 16|8@1+ (1,0) [0|255] "" Vector__XXX
SG_ CDC_config1_drv3_config_val_4 : 24|8@1+ (1,0) [0|255] "" Vector__XXX

BO_ 1566 CDC_Config2_Drv3: 4 Vector__XXX
SG_ CDC_config2_drv3_config_val_1 : 0|8@1+ (1,0) [0|255] "" Vector__XXX
SG_ CDC_config2_drv3_config_val_2 : 8|8@1+ (1,0) [0|255] "" Vector__XXX
SG_ CDC_config2_drv3_config_val_3 : 16|8@1+ (1,0) [0|255] "" Vector__XXX
SG_ CDC_config2_drv3_config_val_4 : 24|8@1+ (1,0) [0|255] "" Vector__XXX

BO_ 1567 CDC_Config3_Drv3: 4 Vector__XXX
SG_ CDC_config3_drv3_config_val_1 : 0|8@1+ (1,0) [0|255] "" Vector__XXX
SG_ CDC_config3_drv3_config_val_2 : 8|8@1+ (1,0) [0|255] "" Vector__XXX
SG_ CDC_config3_drv3_config_val_3 : 16|8@1+ (1,0) [0|255] "" Vector__XXX
SG_ CDC_config3_drv3_config_val_4 : 24|8@1+ (1,0) [0|255] "" Vector__XXX

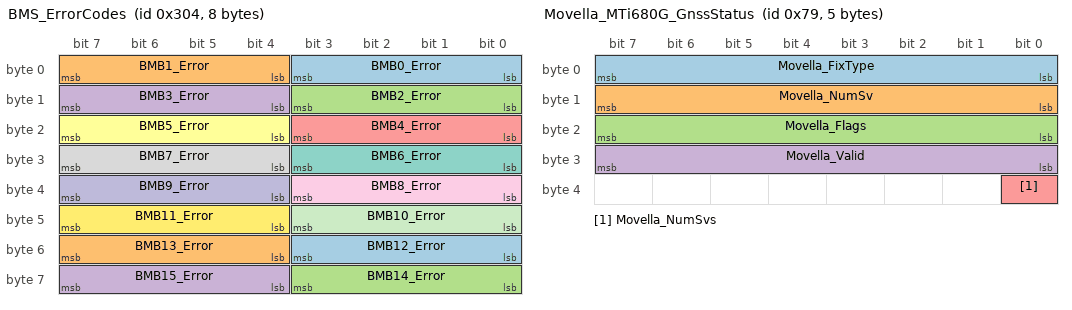
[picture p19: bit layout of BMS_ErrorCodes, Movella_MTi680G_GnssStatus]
BO_ 772 BMS_ErrorCodes: 8 Vector__XXX
SG_ BMB0_Error : 0|4@1+ (1,0) [0|15] "" Vector__XXX
SG_ BMB1_Error : 4|4@1+ (1,0) [0|15] "" Vector__XXX
SG_ BMB2_Error : 8|4@1+ (1,0) [0|15] "" Vector__XXX
SG_ BMB3_Error : 12|4@1+ (1,0) [0|15] "" Vector__XXX
SG_ BMB4_Error : 16|4@1+ (1,0) [0|15] "" Vector__XXX
SG_ BMB5_Error : 20|4@1+ (1,0) [0|15] "" Vector__XXX
SG_ BMB6_Error : 24|4@1+ (1,0) [0|15] "" Vector__XXX
SG_ BMB7_Error : 28|4@1+ (1,0) [0|15] "" Vector__XXX
SG_ BMB8_Error : 32|4@1+ (1,0) [0|15] "" Vector__XXX
SG_ BMB9_Error : 36|4@1+ (1,0) [0|15] "" Vector__XXX
SG_ BMB10_Error : 40|4@1+ (1,0) [0|15] "" Vector__XXX
SG_ BMB11_Error : 44|4@1+ (1,0) [0|15] "" Vector__XXX
SG_ BMB12_Error : 48|4@1+ (1,0) [0|15] "" Vector__XXX
SG_ BMB13_Error : 52|4@1+ (1,0) [0|15] "" Vector__XXX
SG_ BMB14_Error : 56|4@1+ (1,0) [0|15] "" Vector__XXX
SG_ BMB15_Error : 60|4@1+ (1,0) [0|15] "" Vector__XXX

BO_ 1317 DIM_DAQ_TEXT: 5 Vector__XXX
SG_ Address : 0|8@1+ (1,0) [0|255] "" Vector__XXX
SG_ Data0 : 8|8@1+ (1,0) [0|255] "" Vector__XXX
SG_ Data1 : 16|8@1+ (1,0) [0|255] "" Vector__XXX
SG_ Data2 : 24|8@1+ (1,0) [0|255] "" Vector__XXX
SG_ Data3 : 32|8@1+ (1,0) [0|255] "" Vector__XXX

BO_ 1616 DAQ_FR_STRAIN_0: 8 Vector__XXX
SG_ FR_FORCE_0 : 0|32@1- (1,0) [-2147483648|2147483647] "" Vector__XXX
SG_ FR_FORCE_1 : 32|32@1- (1,0) [-2147483648|2147483647] "N" Vector__XXX

BO_ 1617 DAQ_FR_STRAIN_1: 8 Vector__XXX
SG_ FR_FORCE_2 : 0|32@1- (1,0) [-2147483648|2147483647] "" Vector__XXX
SG_ FR_FORCE_3 : 32|32@1- (1,0) [-2147483648|2147483647] "" Vector__XXX

BO_ 1618 DAQ_FR_THERM: 8 Vector__XXX
SG_ FR_THERM_0 : 0|16@1+ (1,0) [0|65535] "" Vector__XXX
SG_ FR_THERM_1 : 16|16@1- (1,0) [-32768|32767] "" Vector__XXX
SG_ FR_THERM_2 : 32|16@1+ (1,0) [0|65535] "" Vector__XXX
SG_ FR_THERM_3 : 48|16@1+ (1,0) [0|65535] "" Vector__XXX

BO_ 1619 DAQ_FR_DAMPER: 8 Vector__XXX
SG_ FR_DAMPER_MM : 0|32@1+ (1,0) [0|4294967295] "" Vector__XXX
SG_ FR_DAMPER_ADC : 32|32@1+ (1,0) [0|4294967295] "" Vector__XXX

BO_ 1620 DAQ_FR_ANEMOMETER: 8 Vector__XXX
SG_ FR_AIRSPEED_MPH : 0|32@1+ (1,0) [0|4294967295] "" Vector__XXX
SG_ FR_AIRSPEED_ADC : 32|32@1+ (1,0) [0|4294967295] "" Vector__XXX

BO_ 1621 DAQ_RR_STRAIN_0: 8 Vector__XXX
SG_ RR_FORCE_0 : 0|32@1- (1,0) [-2147483648|2147483647] "" Vector__XXX
SG_ RR_FORCE_1 : 32|32@1- (1,0) [-2147483648|2147483647] "N" Vector__XXX

BO_ 1622 DAQ_RR_STRAIN_1: 8 Vector__XXX
SG_ RR_FORCE_2 : 0|32@1- (1,0) [-2147483648|2147483647] "" Vector__XXX
SG_ RR_FORCE_3 : 32|32@1- (1,0) [-2147483648|2147483647] "" Vector__XXX

BO_ 1623 DAQ_RR_THERM: 8 Vector__XXX
SG_ RR_THERM_0 : 0|16@1+ (1,0) [0|65535] "" Vector__XXX
SG_ RR_THERM_1 : 16|16@1- (1,0) [-32768|32767] "" Vector__XXX
SG_ RR_THERM_2 : 32|16@1+ (1,0) [0|65535] "" Vector__XXX
SG_ RR_THERM_3 : 48|16@1+ (1,0) [0|65535] "" Vector__XXX

BO_ 1624 DAQ_RR_DAMPER: 8 Vector__XXX
SG_ FR_DAMPER_MM : 0|16@1+ (1,0) [0|4294967295] "" Vector__XXX
SG_ FR_DAMPER_ADC : 16|16@1+ (1,0) [0|4294967295] "" Vector__XXX
SG_ FL_DAMPER_MM : 32|16@1+ (1,0) [0|4294967295] "" Vector__XXX
SG_ FL_DAMPER_ADC : 48|16@1+ (1,0) [0|4294967295] "" Vector__XXX

BO_ 1625 DAQ_RR_ANEMOMETER: 8 Vector__XXX
SG_ RR_AIRSPEED_MPH : 0|32@1+ (1,0) [0|4294967295] "" Vector__XXX
SG_ RR_AIRSPEED_ADC : 32|32@1+ (1,0) [0|4294967295] "" Vector__XXX

BO_ 1626 DAQ_RL_STRAIN_0: 8 Vector__XXX
SG_ RL_FORCE_0 : 0|32@1- (1,0) [-2147483648|2147483647] "" Vector__XXX
SG_ RL_FORCE_1 : 32|32@1- (1,0) [-2147483648|2147483647] "N" Vector__XXX

BO_ 1627 DAQ_RL_STRAIN_1: 8 Vector__XXX
SG_ RL_FORCE_2 : 0|32@1- (1,0) [-2147483648|2147483647] "" Vector__XXX
SG_ RL_FORCE_3 : 32|32@1- (1,0) [-2147483648|2147483647] "" Vector__XXX

BO_ 1628 DAQ_RL_THERM: 8 Vector__XXX
SG_ RL_THERM_0 : 0|16@1+ (1,0) [0|65535] "" Vector__XXX
SG_ RL_THERM_1 : 16|16@1- (1,0) [-32768|32767] "" Vector__XXX
SG_ RL_THERM_2 : 32|16@1+ (1,0) [0|65535] "" Vector__XXX
SG_ RL_THERM_3 : 48|16@1+ (1,0) [0|65535] "" Vector__XXX

BO_ 1629 DAQ_RL_DAMPER: 8 Vector__XXX
SG_ RL_DAMPER_MM : 0|32@1+ (1,0) [0|4294967295] "" Vector__XXX
SG_ RL_DAMPER_ADC : 32|32@1+ (1,0) [0|4294967295] "" Vector__XXX

BO_ 1630 DAQ_RL_ANEMOMETER: 8 Vector__XXX
SG_ RL_AIRSPEED_MPH : 0|32@1+ (1,0) [0|4294967295] "" Vector__XXX
SG_ RL_AIRSPEED_ADC : 32|32@1+ (1,0) [0|4294967295] "" Vector__XXX

BO_ 1631 DAQ_FL_STRAIN_0: 8 Vector__XXX
SG_ FL_FORCE_0 : 0|32@1- (1,0) [-2147483648|2147483647] "" Vector__XXX
SG_ FL_FORCE_1 : 32|32@1- (1,0) [-2147483648|2147483647] "N" Vector__XXX

BO_ 1632 DAQ_FL_STRAIN_1: 8 Vector__XXX
SG_ FL_FORCE_2 : 0|32@1- (1,0) [-2147483648|2147483647] "" Vector__XXX
SG_ FL_FORCE_3 : 32|32@1- (1,0) [-2147483648|2147483647] "" Vector__XXX

BO_ 1633 DAQ_FL_THERM: 8 Vector__XXX
SG_ FL_THERM_0 : 0|16@1+ (1,0) [0|65535] "" Vector__XXX
SG_ FL_THERM_1 : 16|16@1- (1,0) [-32768|32767] "" Vector__XXX
SG_ FL_THERM_2 : 32|16@1+ (1,0) [0|65535] "" Vector__XXX
SG_ FL_THERM_3 : 48|16@1+ (1,0) [0|65535] "" Vector__XXX

BO_ 1634 DAQ_FL_DAMPER: 8 Vector__XXX
SG_ FL_DAMPER_MM : 0|32@1+ (1,0) [0|4294967295] "" Vector__XXX
SG_ FL_DAMPER_ADC : 32|32@1+ (1,0) [0|4294967295] "" Vector__XXX

BO_ 1635 DAQ_FL_ANEMOMETER: 8 Vector__XXX
SG_ FL_AIRSPEED_MPH : 0|32@1+ (1,0) [0|4294967295] "" Vector__XXX
SG_ FL_AIRSPEED_ADC : 32|32@1+ (1,0) [0|4294967295] "" Vector__XXX

BO_ 265 Memorator_Heartbeat: 1 Vector__XXX
SG_ State : 0|8@1+ (1,0) [0|255] "" Vector__XXX

BO_ 262 HVI_Heartbeat: 8 Vector__XXX
SG_ HVI_Current : 0|16@1- (0.1,0) [-3276.8|3276.7] "A" Vector__XXX
SG_ HVI_Voltage : 16|16@1+ (0.01,0) [0|655.35] "V" Vector__XXX
SG_ HVI_Power : 32|32@1- (0.001,0) [-2147483.648|2147483.647] "kW" Vector__XXX

BO_ 263 CCM_Heartbeat: 6 Vector__XXX
SG_ CCM_state : 0|8@1+ (1,0) [0|255] "" Vector__XXX
SG_ CCM_ChargerVoltage : 8|16@1+ (1,0) [0|65535] "dV" Vector__XXX
SG_ CCM_ChargerCurrent : 24|16@1+ (1,0) [0|65535] "dA" Vector__XXX
SG_ CCM_ChargerDisabled : 40|8@1+ (1,0) [0|255] "" Vector__XXX

BO_ 1911 DAQ_AUTO_TEST: 1 Vector__XXX
SG_ TEST_STATUS : 7|1@1+ (1,0) [0|1] "" Vector__XXX
SG_ TEST_ID : 0|7@1+ (1,0) [0|127] "" Vector__XXX

BO_ 2022 CDC_Solver_Inputs: 8 Vector__XXX
SG_ Moment_REQ : 0|32@1- (1,0) [-3.4E038|3.4E038] "" Vector__XXX
SG_ Lin_Accel_REQ : 32|32@1- (1,0) [-3.4E038|3.4E038] "" Vector__XXX

BO_ 2032 CDC_Solver_Outputs: 8 Vector__XXX
SG_ Torque_FL : 0|16@1- (1,0) [-32768|32767] "" Vector__XXX
SG_ Torque_FR : 16|16@1- (1,0) [-32768|32767] "" Vector__XXX
SG_ Torque_RL : 32|16@1- (1,0) [-32768|32767] "" Vector__XXX
SG_ Torque_RR : 48|16@1- (1,0) [-32768|32767] "" Vector__XXX

BO_ 2030 CDC_Solver_Settings: 6 Vector__XXX
SG_ k_lin : 0|16@1+ (1,0) [0|65535] "Unit" Vector__XXX
SG_ k_yaw : 16|16@1+ (1,0) [0|65535] "Unit" Vector__XXX
SG_ k_tie : 32|16@1+ (1,0) [0|65535] "Unit" Vector__XXX

BO_ 308 HVC_Balance_Command: 4 Vector__XXX
SG_ Enable : 0|8@1+ (1,0) [0|1] "" Vector__XXX
SG_ Threshold : 16|16@1+ (1,0) [2450|4280] "mV" Vector__XXX

BO_ 2033 VSM_Git: 8 Vector__XXX
SG_ Commit_Hash_VSM : 0|32@1+ (1,0) [0|4294967295] "" Vector__XXX
SG_ Dirty_VSM : 32|8@1+ (1,0) [0|255] "" Vector__XXX

BO_ 2034 HVC_Git: 3 Vector__XXX
SG_ Commit_Hash_HVC : 0|16@1+ (1,0) [0|65535] "" Vector__XXX
SG_ Dirty_HVC : 16|8@1+ (1,0) [0|255] "" Vector__XXX

BO_ 2035 PTC_Git: 8 Vector__XXX
SG_ Commit_Hash_PTC : 0|32@1+ (1,0) [0|4294967295] "" Vector__XXX
SG_ Dirty_PTC : 32|8@1+ (1,0) [0|255] "" Vector__XXX

BO_ 2036 CDC_Git: 8 Vector__XXX
SG_ Commit_Hash_CDC : 0|32@1+ (1,0) [0|4294967295] "" Vector__XXX
SG_ Dirty_CDC : 32|8@1+ (1,0) [0|255] "" Vector__XXX

BO_ 2037 DIM_Git: 8 Vector__XXX
SG_ Commit_Hash_DIM : 0|32@1+ (1,0) [0|4294967295] "" Vector__XXX
SG_ Dirty_DIM : 32|8@1+ (1,0) [0|255] "" Vector__XXX

BO_ 2038 RAM_Git: 8 Vector__XXX
SG_ Commit_Hash_RAM : 0|32@1+ (1,0) [0|4294967295] "" Vector__XXX
SG_ Dirty_RAM : 32|8@1+ (1,0) [0|255] "" Vector__XXX

BO_ 1908 Movella_MTi680G_Quaternion: 8 Vector__XXX
SG_ Movella_w : 7|16@0- (3.05185094759972E-005,0) [-1.00003051850948|1] "" Vector__XXX
SG_ Movella_x : 23|16@0- (3.05185094759972E-005,0) [-1.00003051850948|1] "" Vector__XXX
SG_ Movella_y : 39|16@0- (3.05185094759972E-005,0) [-1.00003051850948|1] "" Vector__XXX
SG_ Movella_z : 55|16@0- (3.05185094759972E-005,0) [-1.00003051850948|1] "" Vector__XXX

BO_ 1905 Movella_Mti680G_GroupCounter: 2 Vector__XXX
SG_ Movella_GroupCounter : 7|16@0+ (1,0) [0|65535] "" Vector__XXX

BO_ 1909 Movella_MTi680G_EulerAngles: 6 Vector__XXX
SG_ Movella_Roll : 7|16@0- (0.0078125,0) [-256|255.9921875] "deg" Vector__XXX
SG_ Movella_Pitch : 23|16@0- (0.0078125,0) [-256|255.9921875] "deg" Vector__XXX
SG_ Movella_Yaw : 39|16@0- (0.0078125,0) [-256|255.9921875] "deg" Vector__XXX

BO_ 1918 Movella_MTi680G_Acceleration: 6 Vector__XXX
SG_ Movella_AccX : 7|16@0- (0.00390625,0) [-128|127.99609375] "m/s^2" Vector__XXX
SG_ Movella_AccY : 23|16@0- (0.00390625,0) [-128|127.99609375] "m/s^2" Vector__XXX
SG_ Movella_AccZ : 39|16@0- (0.00390625,0) [-128|127.99609375] "m/s^2" Vector__XXX

BO_ 1913 Movella_MTi680G_Temperature: 2 Vector__XXX
SG_ Movella_Temperature : 7|16@0- (0.00390625,0) [-128|127.99609375] "deg C" Vector__XXX

BO_ 1914 Movella_MTi680G_BaroPressure: 4 Vector__XXX
SG_ Movella_Pressure : 7|32@0+ (1,0) [0|4294967295] "Pa" Vector__XXX

BO_ 1904 Movella_MTi680G_SampleTime: 4 Vector__XXX
SG_ Movella_SampleTime : 7|32@0+ (1,0) [0|4294967295] "" Vector__XXX

BO_ 1910 Movella_MTi680G_RateOfTurn: 6 Vector__XXX
SG_ Movella_GyroX : 7|16@0- (0.001953125,0) [-64|63.998046875] "rad/s" Vector__XXX
SG_ Movella_GyroY : 23|16@0- (0.001953125,0) [-64|63.998046875] "rad/s" Vector__XXX
SG_ Movella_GyroZ : 39|16@0- (0.001953125,0) [-64|63.998046875] "rad/s" Vector__XXX

BO_ 1912 Movella_MTi680G_MagneticField: 6 Vector__XXX
SG_ Movella_MagX : 7|16@0- (0.0009765625,0) [-32|31.9990234375] "a.u." Vector__XXX
SG_ Movella_MagY : 23|16@0- (0.0009765625,0) [-32|31.9990234375] "a.u." Vector__XXX
SG_ Movella_MagZ : 39|16@0- (0.0009765625,0) [-32|31.9990234375] "a.u." Vector__XXX

BO_ 1917 Movella_MTi680G_Velocity: 6 Vector__XXX
SG_ Movella_VelX : 7|16@0- (0.015625,0) [-512|511.984375] "m/s" Vector__XXX
SG_ Movella_VelY : 23|16@0- (0.015625,0) [-512|511.984375] "m/s" Vector__XXX
SG_ Movella_VelZ : 39|16@0- (0.015625,0) [-512|511.984375] "m/s" Vector__XXX

BO_ 121 Movella_MTi680G_GnssStatus: 5 Vector__XXX
SG_ Movella_FixType : 7|8@0+ (1,0) [0|255] "" Vector__XXX
SG_ Movella_NumSv : 15|8@0+ (1,0) [0|255] "" Vector__XXX
SG_ Movella_Flags : 23|8@0+ (1,0) [0|255] "" Vector__XXX
SG_ Movella_Valid : 31|8@0+ (1,0) [0|255] "" Vector__XXX
SG_ Movella_NumSvs : 32|1@0+ (1,0) [0|1] "" Vector__XXX

BO_ 1915 Movella_MTi680G_Coordinates: 8 Vector__XXX
SG_ Movella_Latitude : 7|32@0- (5.96046447753906E-008,0) [-128|127.999999940395] "deg" Vector__XXX
SG_ Movella_Longitude : 39|32@0- (1.19209289550781E-007,0) [-255.999999999999|255.99999988079] "deg" Vector__XXX

BO_ 706 DCM_COG_Velocity: 8 Vector__XXX
SG_ cog_x : 0|16@1- (0.01,0) [-327.68|327.67] "m/s" Vector__XXX
SG_ cog_y : 16|16@1- (0.01,0) [-327.68|327.67] "m/s" Vector__XXX
SG_ slip_angle : 32|32@1- (1,0) [-3.4E038|3.4E038] "rad" Vector__XXX

BO_ 722 DCM_Front_Velocity: 8 Vector__XXX
SG_ fl_x : 0|16@1- (0.01,0) [-327.68|327.67] "m/s" Vector__XXX
SG_ fl_y : 16|16@1- (0.01,0) [-327.68|327.67] "m/s" Vector__XXX
SG_ fr_x : 32|16@1- (0.01,0) [-327.68|327.67] "m/s" Vector__XXX
SG_ fr_y : 48|16@1- (0.01,0) [-327.68|327.67] "m/s" Vector__XXX

BO_ 738 DCM_Rear_Velocity: 8 Vector__XXX
SG_ rl_x : 0|16@1- (0.01,0) [-327.68|327.67] "m/s" Vector__XXX
SG_ rl_y : 16|16@1- (0.01,0) [-327.68|327.67] "m/s" Vector__XXX
SG_ rr_x : 32|16@1- (0.01,0) [-327.68|327.67] "m/s" Vector__XXX
SG_ rr_y : 48|16@1- (0.01,0) [-327.68|327.67] "m/s" Vector__XXX

BO_ 1906 Movella_MTi860G_Status: 4 Vector__XXX
SG_ Movella_have_gnss_time_pulse : 2|1@1+ (1,0) [0|1] "" Vector__XXX
SG_ Movella_fitler_mode : 0|2@1+ (1,0) [0|3] "" Vector__XXX
SG_ Movella_rtk_status : 3|2@1+ (1,0) [0|3] "" Vector__XXX
SG_ Movella_clipflag_mag_z : 8|1@1+ (1,0) [0|1] "" Vector__XXX
SG_ Movella_clipping_indication : 11|1@1+ (1,0) [0|1] "" Vector__XXX
SG_ Movella_sync_in_marker : 13|1@1+ (1,0) [0|1] "" Vector__XXX
SG_ Movella_sync_out_marker : 14|1@1+ (1,0) [0|1] "" Vector__XXX
SG_ Movella_filter_mode_2 : 15|1@1+ (1,0) [0|1] "" Vector__XXX
SG_ Movella_clipflag_acc_x : 16|1@1+ (1,0) [0|1] "" Vector__XXX
SG_ Movella_clipflag_acc_y : 17|1@1+ (1,0) [0|1] "" Vector__XXX
SG_ Movella_clipflag_acc_z : 18|1@1+ (1,0) [0|1] "" Vector__XXX
SG_ Movella_clipflag_gyr_x : 19|1@1+ (1,0) [0|1] "" Vector__XXX
SG_ Movella_clipflag_gyr_y : 20|1@1+ (1,0) [0|1] "" Vector__XXX
SG_ Movella_clipflag_gyr_z : 21|1@1+ (1,0) [0|1] "" Vector__XXX
SG_ Movella_clipflag_mag_x : 22|1@1+ (1,0) [0|1] "" Vector__XXX
SG_ Movella_clipflag_mag_y : 23|1@1+ (1,0) [0|1] "" Vector__XXX
SG_ Movella_self_test : 24|1@1+ (1,0) [0|1] "" Vector__XXX
SG_ Movella_filter_valid : 25|1@1+ (1,0) [0|1] "" Vector__XXX
SG_ Movella_gnss_fix : 26|1@1+ (1,0) [0|1] "" Vector__XXX
SG_ Movella_no_rotation_update : 27|2@1+ (1,0) [0|3] "" Vector__XXX
SG_ Movella_representative_motion : 29|1@1+ (1,0) [0|1] "" Vector__XXX
SG_ Movella_clock_bias_estimation : 30|1@1+ (1,0) [0|1] "" Vector__XXX

BO_ 1764 DCM_PowerLimit: 4 Vector__XXX
SG_ PowerLimit : 0|32@1- (0.001,0) [-3.4E035|3.4E035] "kW" Vector__XXX

BO_ 309 FSM_Swangle: 8 Vector__XXX
SG_ SwangleRight : 0|32@1- (0.001,0) [-2147483.648|2147483.647] "deg" Vector__XXX
SG_ SwangleLeft : 32|32@1- (0.001,0) [-2147483.648|2147483.647] "deg" Vector__XXX

BO_ 2039 LV_BMS_Voltages1: 6 Vector__XXX
SG_ Cell1 : 0|16@1- (1,0) [-32768|32767] "cV" Vector__XXX
SG_ Cell2 : 16|16@1- (1,0) [-32768|32767] "cV" Vector__XXX
SG_ Cell3 : 32|16@1- (1,0) [-32768|32767] "cV" Vector__XXX

BO_ 2040 LV_BMS_Voltages2: 6 Vector__XXX
SG_ Cell4 : 0|16@1- (1,0) [-32768|32767] "cV" Vector__XXX
SG_ Cell5 : 16|16@1- (1,0) [-32768|32767] "cV" Vector__XXX
SG_ Cell6 : 32|16@1- (1,0) [-32768|32767] "cV" Vector__XXX

BO_ 1632 DAQ_PI_RL_MLX: 2 Vector__XXX
SG_ RL_Avg_Tire_Temp : 0|16@1+ (0.1,0) [0|6553.5] "C" Vector__XXX

BO_ 1633 DAQ_PI_RL_ADC: 6 Vector__XXX
SG_ RL_Linpot : 0|16@1+ (1,0) [0|65535] "" Vector__XXX
SG_ RL_ADC1 : 16|16@1+ (1,0) [0|65535] "" Vector__XXX
SG_ RL_ADC2 : 32|16@1+ (1,0) [0|65535] "" Vector__XXX

BO_ 1634 DAQ_PI_RL_VL: 2 Vector__XXX
SG_ RL_RideHeight : 0|16@1+ (1,0) [0|65535] "" Vector__XXX

BO_ 1648 DAQ_PI_FL_MLX: 2 Vector__XXX
SG_ FL_Avg_Tire_Temp : 0|16@1+ (0.1,0) [0|6553.5] "C" Vector__XXX

BO_ 1649 DAQ_PI_FL_ADC: 6 Vector__XXX
SG_ FL_Linpot : 0|16@1+ (1,0) [0|65535] "" Vector__XXX
SG_ FL_ADC1 : 16|16@1+ (1,0) [0|65535] "" Vector__XXX
SG_ FL_ADC2 : 32|16@1+ (1,0) [0|65535] "" Vector__XXX

BO_ 1650 DAQ_PI_FL_VL: 2 Vector__XXX
SG_ FL_RideHeight : 0|16@1+ (1,0) [0|65535] "" Vector__XXX

BO_ 1664 DAQ_PI_FR_MLX: 2 Vector__XXX
SG_ FR_Avg_Tire_Temp : 0|16@1+ (0.1,0) [0|6553.5] "C" Vector__XXX

BO_ 1665 DAQ_PI_FR_ADC: 6 Vector__XXX
SG_ FR_Linpot : 0|16@1+ (1,0) [0|65535] "" Vector__XXX
SG_ FR_ADC1 : 16|16@1+ (1,0) [0|65535] "" Vector__XXX
SG_ FR_ADC2 : 32|16@1+ (1,0) [0|65535] "" Vector__XXX

BO_ 1666 DAQ_PI_FR_VL: 2 Vector__XXX
SG_ FR_RideHeight : 0|16@1+ (1,0) [0|65535] "" Vector__XXX

BO_ 1680 DAQ_PI_RR_MLX: 2 Vector__XXX
SG_ RR_Avg_Tire_Temp : 0|16@1+ (0.1,0) [0|6553.5] "C" Vector__XXX

BO_ 1681 DAQ_PI_RR_ADC: 6 Vector__XXX
SG_ RR_Linpot : 0|16@1+ (1,0) [0|65535] "" Vector__XXX
SG_ RR_ADC1 : 16|16@1+ (1,0) [0|65535] "" Vector__XXX
SG_ RR_ADC2 : 32|16@1+ (1,0) [0|65535] "" Vector__XXX

BO_ 1682 DAQ_PI_RR_VL: 2 Vector__XXX
SG_ RR_RideHeight : 0|16@1+ (1,0) [0|65535] "" Vector__XXX

BO_ 1624 DAQ_Therm1: 8 Vector__XXX
SG_ Therm_1_1 : 0|32@1+ (1,0) [0|4294967295] "" Vector__XXX
SG_ Therm_1_2 : 32|32@1+ (1,0) [0|4294967295] "" Vector__XXX

BO_ 1625 DAQ_Therm2: 8 Vector__XXX
SG_ Therm_2_1 : 0|32@1+ (1,0) [0|4294967295] "" Vector__XXX
SG_ Therm_2_2 : 32|32@1+ (1,0) [0|4294967295] "" Vector__XXX

CM_ BO_ 1296 "Timeout matrix";
CM_ BO_ 644 "Set ID based on wiring";
CM_ SG_ 644 AMK_FR_TorqueCurrent "Mysterious scaling factor.";
CM_ SG_ 644 AMK_FR_MagnetizingCurrent "Mysterious scaling factor.";
CM_ BO_ 646 "Set ID based on wiring";
CM_ BO_ 389 "Set ID based on wiring";
CM_ SG_ 389 AMK_FR_TorqueLimitPositiv "Giving in 0.1% of nominal torque Mn, where Mn = 9.8 Nm.";
CM_ SG_ 389 AMK_FR_TorqueLimitNegativ "Giving in 0.1% of nominal torque Mn, where Mn = 9.8 Nm.";
CM_ BO_ 648 "Set ID based on wiring";
CM_ SG_ 648 AMK_FL_TorqueCurrent "Mysterious scaling factor.";
CM_ SG_ 648 AMK_FL_MagnetizingCurrent "Mysterious scaling factor.";
CM_ BO_ 650 "Set ID based on wiring";
CM_ BO_ 393 "Set ID based on wiring";
CM_ SG_ 393 AMK_FL_TorqueLimitPositiv "Giving in 0.1% of nominal torque Mn, where Mn = 9.8 Nm.";
CM_ SG_ 393 AMK_FL_TorqueLimitNegativ "Giving in 0.1% of nominal torque Mn, where Mn = 9.8 Nm.";
CM_ BO_ 647 "Set ID based on wiring";
CM_ SG_ 647 AMK_BL_TorqueCurrent "Mysterious scaling factor.";
CM_ SG_ 647 AMK_BL_MagnetizingCurrent "Mysterious scaling factor.";
CM_ BO_ 649 "Set ID based on wiring";
CM_ BO_ 392 "Set ID based on wiring";
CM_ SG_ 392 AMK_BL_TorqueLimitPositiv "Giving in 0.1% of nominal torque Mn, where Mn = 9.8 Nm.";
CM_ SG_ 392 AMK_BL_TorqueLimitNegativ "Giving in 0.1% of nominal torque Mn, where Mn = 9.8 Nm.";
CM_ BO_ 643 "Set ID based on wiring";
CM_ SG_ 643 AMK_BR_TorqueCurrent "Mysterious scaling factor.";
CM_ SG_ 643 AMK_BR_MagnetizingCurrent "Mysterious scaling factor.";
CM_ BO_ 645 "Set ID based on wiring";
CM_ BO_ 388 "Set ID based on wiring";
CM_ SG_ 388 AMK_BR_TorqueLimitPositiv "Giving in 0.1% of nominal torque Mn, where Mn = 9.8 Nm.";
CM_ SG_ 388 AMK_BR_TorqueLimitNegativ "Giving in 0.1% of nominal torque Mn, where Mn = 9.8 Nm.";
CM_ BO_ 2023 "This CAN id is used for communication between the energy meter and the download tool.";
CM_ BO_ 2031 "This CAN id is used for communication between the energy meter and the download tool.";
CM_ SG_ 1952 squelch "0 for listen, 1 - 8 for transmit";
CM_ SG_ 1698 RTC_Error "For interpreting this, see comments in code.";
CM_ SG_ 1714 RTC_Error_In "For interpreting this, see comments in code.";
CM_ SG_ 1911 TEST_STATUS "1- START TEST, 0 - STOP TEST";
CM_ SG_ 1911 TEST_ID "Randomly generated test id sent everytime the car states up";
CM_ SG_ 1904 Movella_SampleTime "10kHz ticks";

BA_DEF_  "BusType" STRING ;
BA_DEF_ BO_  "GenMsgCycleTime" INT 0 65535;
BA_DEF_ SG_  "GenSigStartValue" FLOAT -3.4E+038 3.4E+038;

BA_DEF_DEF_  "BusType" "CAN";
BA_DEF_DEF_  "GenMsgCycleTime" 0;
BA_DEF_DEF_  "GenSigStartValue" 0;

BA_ "GenMsgCycleTime" BO_ 256 10;
BA_ "GenMsgCycleTime" BO_ 272 10;
BA_ "GenMsgCycleTime" BO_ 512 5;
BA_ "GenMsgCycleTime" BO_ 1296 10000;
BA_ "GenMsgCycleTime" BO_ 1328 100;
BA_ "GenMsgCycleTime" BO_ 257 10;
BA_ "GenMsgCycleTime" BO_ 304 10;
BA_ "GenMsgCycleTime" BO_ 258 10;
BA_ "GenMsgCycleTime" BO_ 1298 1000;
BA_ "GenMsgCycleTime" BO_ 1282 1000;
BA_ "GenMsgCycleTime" BO_ 562 100;
BA_ "GenMsgCycleTime" BO_ 594 100;
BA_ "GenMsgCycleTime" BO_ 610 100;
BA_ "GenMsgCycleTime" BO_ 626 100;
BA_ "GenMsgCycleTime" BO_ 642 100;
BA_ "GenMsgCycleTime" BO_ 658 100;
BA_ "GenMsgCycleTime" BO_ 674 100;
BA_ "GenMsgCycleTime" BO_ 690 100;
BA_ "GenMsgCycleTime" BO_ 773 10;
BA_ "GenMsgCycleTime" BO_ 259 10;
BA_ "GenMsgCycleTime" BO_ 307 10;
BA_ "GenMsgCycleTime" BO_ 1331 100;
BA_ "GenMsgCycleTime" BO_ 1347 100;
BA_ "GenMsgCycleTime" BO_ 1363 100;
BA_ "GenMsgCycleTime" BO_ 260 10;
BA_ "GenMsgCycleTime" BO_ 1333 100;
BA_ "GenMsgCycleTime" BO_ 565 100;
BA_ "GenMsgCycleTime" BO_ 1301 100;
BA_ "GenMsgCycleTime" BO_ 1349 1000;
BA_ "GenMsgCycleTime" BO_ 261 10;
BA_ "GenMsgCycleTime" BO_ 548 100;
BA_ "GenMsgCycleTime" BO_ 564 100;
BA_ "GenMsgCycleTime" BO_ 580 100;
BA_ "GenMsgCycleTime" BO_ 788 100;
BA_ "GenMsgCycleTime" BO_ 1332 100;
BA_ "GenMsgCycleTime" BO_ 769 10;
BA_ "GenMsgCycleTime" BO_ 770 10;
BA_ "GenMsgCycleTime" BO_ 771 10;
BA_ "GenMsgCycleTime" BO_ 896 100;
BA_ "GenMsgCycleTime" BO_ 897 1000;
BA_ "GenMsgCycleTime" BO_ 898 100;
BA_ "GenMsgCycleTime" BO_ 899 1000;
BA_ "GenMsgCycleTime" BO_ 900 100;
BA_ "GenMsgCycleTime" BO_ 901 1000;
BA_ "GenMsgCycleTime" BO_ 902 100;
BA_ "GenMsgCycleTime" BO_ 903 1000;
BA_ "GenMsgCycleTime" BO_ 904 100;
BA_ "GenMsgCycleTime" BO_ 905 1000;
BA_ "GenMsgCycleTime" BO_ 906 100;
BA_ "GenMsgCycleTime" BO_ 907 1000;
BA_ "GenMsgCycleTime" BO_ 908 100;
BA_ "GenMsgCycleTime" BO_ 909 1000;
BA_ "GenMsgCycleTime" BO_ 910 100;
BA_ "GenMsgCycleTime" BO_ 911 1000;
BA_ "GenMsgCycleTime" BO_ 912 100;
BA_ "GenMsgCycleTime" BO_ 913 1000;
BA_ "GenMsgCycleTime" BO_ 914 100;
BA_ "GenMsgCycleTime" BO_ 915 1000;
BA_ "GenMsgCycleTime" BO_ 916 100;
BA_ "GenMsgCycleTime" BO_ 917 1000;
BA_ "GenMsgCycleTime" BO_ 918 100;
BA_ "GenMsgCycleTime" BO_ 919 1000;
BA_ "GenMsgCycleTime" BO_ 920 100;
BA_ "GenMsgCycleTime" BO_ 921 1000;
BA_ "GenMsgCycleTime" BO_ 922 100;
BA_ "GenMsgCycleTime" BO_ 923 1000;
BA_ "GenMsgCycleTime" BO_ 924 100;
BA_ "GenMsgCycleTime" BO_ 925 1000;
BA_ "GenMsgCycleTime" BO_ 926 100;
BA_ "GenMsgCycleTime" BO_ 927 1000;
BA_ "GenMsgCycleTime" BO_ 644 5;
BA_ "GenMsgCycleTime" BO_ 646 5;
BA_ "GenMsgCycleTime" BO_ 389 1;
BA_ "GenMsgCycleTime" BO_ 648 5;
BA_ "GenMsgCycleTime" BO_ 650 5;
BA_ "GenMsgCycleTime" BO_ 393 1;
BA_ "GenMsgCycleTime" BO_ 647 5;
BA_ "GenMsgCycleTime" BO_ 649 5;
BA_ "GenMsgCycleTime" BO_ 392 1;
BA_ "GenMsgCycleTime" BO_ 643 5;
BA_ "GenMsgCycleTime" BO_ 645 5;
BA_ "GenMsgCycleTime" BO_ 388 1;
BA_ "GenMsgCycleTime" BO_ 2021 100;
BA_ "GenMsgCycleTime" BO_ 1698 1000;
BA_ "GenMsgCycleTime" BO_ 1714 1000;
BA_ "GenMsgCycleTime" BO_ 1730 1000;
BA_ "GenMsgCycleTime" BO_ 1324 200;
BA_ "GenMsgCycleTime" BO_ 1325 100;
BA_ "GenMsgCycleTime" BO_ 1536 1000;
BA_ "GenMsgCycleTime" BO_ 1537 1000;
BA_ "GenMsgCycleTime" BO_ 1538 1000;
BA_ "GenMsgCycleTime" BO_ 1539 1000;
BA_ "GenMsgCycleTime" BO_ 1540 1000;
BA_ "GenMsgCycleTime" BO_ 1541 1000;
BA_ "GenMsgCycleTime" BO_ 1542 1000;
BA_ "GenMsgCycleTime" BO_ 1543 1000;
BA_ "GenMsgCycleTime" BO_ 1544 1000;
BA_ "GenMsgCycleTime" BO_ 1545 1000;
BA_ "GenMsgCycleTime" BO_ 1546 1000;
BA_ "GenMsgCycleTime" BO_ 1547 1000;
BA_ "GenMsgCycleTime" BO_ 1548 1000;
BA_ "GenMsgCycleTime" BO_ 1549 1000;
BA_ "GenMsgCycleTime" BO_ 1550 1000;
BA_ "GenMsgCycleTime" BO_ 1551 1000;
BA_ "GenMsgCycleTime" BO_ 1554 1000;
BA_ "GenMsgCycleTime" BO_ 1555 1000;
BA_ "GenMsgCycleTime" BO_ 1556 1000;
BA_ "GenMsgCycleTime" BO_ 1557 1000;
BA_ "GenMsgCycleTime" BO_ 1558 1000;
BA_ "GenMsgCycleTime" BO_ 1559 1000;
BA_ "GenMsgCycleTime" BO_ 1560 1000;
BA_ "GenMsgCycleTime" BO_ 1561 1000;
BA_ "GenMsgCycleTime" BO_ 1562 1000;
BA_ "GenMsgCycleTime" BO_ 1563 1000;
BA_ "GenMsgCycleTime" BO_ 1564 1000;
BA_ "GenMsgCycleTime" BO_ 1565 1000;
BA_ "GenMsgCycleTime" BO_ 1566 1000;
BA_ "GenMsgCycleTime" BO_ 1567 1000;
BA_ "GenMsgCycleTime" BO_ 263 1000;
BA_ "GenMsgCycleTime" BO_ 308 10;
BA_ "GenMsgCycleTime" BO_ 2033 1000;
BA_ "GenMsgCycleTime" BO_ 2034 1000;
BA_ "GenMsgCycleTime" BO_ 2035 1000;
BA_ "GenMsgCycleTime" BO_ 2036 1000;
BA_ "GenMsgCycleTime" BO_ 2037 1000;
BA_ "GenMsgCycleTime" BO_ 2038 1000;
BA_ "GenMsgCycleTime" BO_ 1632 125;
BA_ "GenMsgCycleTime" BO_ 1633 5;
BA_ "GenMsgCycleTime" BO_ 1634 50;
BA_ "GenMsgCycleTime" BO_ 1648 125;
BA_ "GenMsgCycleTime" BO_ 1649 5;
BA_ "GenMsgCycleTime" BO_ 1650 50;
BA_ "GenMsgCycleTime" BO_ 1664 125;
BA_ "GenMsgCycleTime" BO_ 1665 5;
BA_ "GenMsgCycleTime" BO_ 1666 50;
BA_ "GenMsgCycleTime" BO_ 1680 125;
BA_ "GenMsgCycleTime" BO_ 1681 5;
BA_ "GenMsgCycleTime" BO_ 1682 50;
BA_ "GenMsgCycleTime" BO_ 1624 100;
BA_ "GenMsgCycleTime" BO_ 1625 100;

BA_ "GenSigStartValue" SG_ 1315 Power_Stage_Temp 40;

VAL_ 256 VSM_state 0 "UNKNOWN" 1 "GLV_ON" 2 "HV_EN" 3 "RTD" 4 "ERROR" 5 "CLEAR_ERROR" ;
VAL_ 272 VSM_internalState 0 "ERROR" 1 "CLEAR_ERROR" 2 "GLV_ON" 3 "REQ_PRECHARGE" 4 "RUN_BMS" 5 "DCDC_EN" 6 "INVERTER_EN" 7 "HV_EN" 8 "RTD" 9 "COOLING_OFF" 10 "DCDC_OFF" ;
VAL_ 257 HVC_Mode 0 "ERROR" 1 "IDLE" 2 "START" 4 "RUN" 8 "CHARGE" ;
VAL_ 257 HVC_State 0 "ERROR" 1 "DISCHARGE" 2 "STANDBY" 3 "DRIVE_PRECHARGE" 4 "DRIVE_PRECHARGE_COMPLETE" 5 "DRIVE" 6 "CHARGE_PRECHARGE" 7 "CHARGE_PRECHARGE_COMPLETE" 8 "CHARGE_TRICKLE" 9 "CHARGE_CONSTANT_CURRENT" 10 "CHARGE_CONSTANT_VOLTAGE" 11 "CLEAR_ERROR" 12 "UNKNOWN" ;
VAL_ 304 HVC_modeRequest 0 "ERROR" 1 "IDLE" 2 "START" 4 "RUN" 8 "CHARGE" ;
VAL_ 258 CDC_state 0 "UNKNOWN" 1 "GLV_ON" 2 "HV_EN" 3 "RTD" 4 "ERROR" 5 "CLEAR_ERROR" ;
VAL_ 259 FSM_state 0 "UNKNOWN" 1 "GLV_ON" 2 "HV_EN" 3 "RTD" 4 "ERROR" 5 "CLEAR_ERROR" ;
VAL_ 260 DIM_state 0 "UNKNOWN" 1 "GLV_ON" 2 "HV_EN" 3 "RTD" 4 "ERROR" 5 "CLEAR_ERROR" ;
VAL_ 565 DIM_requestState 0 "UNKNOWN" 1 "GLV_ON" 2 "HV_EN" 3 "RTD" 4 "ERROR" 5 "CLEAR_ERROR" ;
VAL_ 565 DIM_requestGear 0 "UNKNOWN" 1 "SLOW" 2 "FAST" 3 "ENDURANCE" 4 "AUTO-X" 5 "SKIDPAD" 6 "ACCEL" 7 "TEST" 8 "REVERSE" ;
VAL_ 565 DIM_requestDRSMode 0 "DRS_CLOSED" 1 "DRS_OPEN" 2 "DRS_TOGGLE" 3 "DRS_HOLD" 4 "DRS_AUTO" 5 "DRS_UNKNOWN" ;
VAL_ 261 PTC_state 0 "UNKNOWN" 1 "GLV_ON" 2 "HV_EN" 3 "RTD" 4 "ERROR" 5 "CLEAR_ERROR" ;
VAL_ 1794 SBG_Solution_Mode 0 "Uninitialized" 1 "Vertical_Gyro_Only" 2 "Orientation_Only" 3 "Nav_Velocity" 4 "Full_Nav" ;
VAL_ 1024 EMD_VoltageGain 0 "x1" 1 "x2" 2 "x4" 3 "x8" 4 "x16" 5 "x32" ;
VAL_ 1024 EMD_CurrentGain 0 "x1" 1 "x2" 2 "x4" 3 "x8" 4 "x16" 5 "x32" ;
VAL_ 263 CCM_state 0 "ERROR" 1 "CLEAR_ERROR" 2 "CLEAR_HVC" 3 "IDLE_HVC" 4 "STANDBY" 5 "CHARGE_REQ" 6 "CHARGE" 7 "SLOW_CHARGE" 8 "SHUTDOWN" ;
VAL_ 308 Enable 0 "BALANCE_DIS" 1 "BALANCE_EN" ;
VAL_ 1906 Movella_fitler_mode 0 "Without GNSS (filter profile is in VRU mode)" 1 "Coasting mode (GNSS has been lost <60 sec ago)" 3 "With GNSS (default mode)" ;

SIG_VALTYPE_ 512 VSM_HE_CoulombCount : 1;
SIG_VALTYPE_ 642 CDC_Latitude : 1;
SIG_VALTYPE_ 642 CDC_Longitude : 1;
SIG_VALTYPE_ 1860 SBG_Velocity_ODO : 1;
SIG_VALTYPE_ 1862 SBG_Pressure_IMU : 1;
SIG_VALTYPE_ 1862 SBG_Altitude_IMU : 1;
SIG_VALTYPE_ 2021 controls_pid : 1;
SIG_VALTYPE_ 1730 CDC_Odometer : 1;
SIG_VALTYPE_ 1325 Power_Limit_Max_Violation_W : 1;
SIG_VALTYPE_ 2024 slipRatio_FL : 1;
SIG_VALTYPE_ 2024 slipRatio_FR : 1;
SIG_VALTYPE_ 2025 slipRatio_RL : 1;
SIG_VALTYPE_ 2025 slipRatio_RR : 1;
SIG_VALTYPE_ 2026 setPoint_FL : 1;
SIG_VALTYPE_ 2026 setPoint_FR : 1;
SIG_VALTYPE_ 2027 setPoint_RL : 1;
SIG_VALTYPE_ 2027 setPoint_RR : 1;
SIG_VALTYPE_ 2028 vel_calc_FL : 1;
SIG_VALTYPE_ 2028 vel_calc_FR : 1;
SIG_VALTYPE_ 2029 vel_calc_RL : 1;
SIG_VALTYPE_ 2029 vel_calc_RR : 1;
SIG_VALTYPE_ 2022 Moment_REQ : 1;
SIG_VALTYPE_ 2022 Lin_Accel_REQ : 1;
SIG_VALTYPE_ 706 slip_angle : 1;
SIG_VALTYPE_ 1764 PowerLimit : 1;
